CM_ "AUTOGENERATED FILE, DO NOT EDIT";

CM_ "lexus_ls600h.dbc starts here";
BU_: XXX CGW EPS SCM STM32G474_HRR CAN_Master

CM_ "Lexus LS600h candidate DBC derived from sustained CAN traffic in routes 9f2573520aa994fd/00000001--93ba1d9657 and 9f2573520aa994fd/00000004--52b0dd2646.";
CM_ "Only messages present in every segment of their source capture are included. One-shot diagnostic traffic is omitted; unknown messages use raw byte signals until their layouts are identified.";

BO_ 32 LS600H_020: 7 XXX
 SG_ LS600H_020_BYTE_0 : 0|8@1+ (1,0) [0|255] "" XXX
 SG_ LS600H_020_BYTE_1 : 8|8@1+ (1,0) [0|255] "" XXX
 SG_ LS600H_020_BYTE_2 : 16|8@1+ (1,0) [0|255] "" XXX
 SG_ LS600H_020_BYTE_3 : 24|8@1+ (1,0) [0|255] "" XXX
 SG_ LS600H_020_BYTE_4 : 32|8@1+ (1,0) [0|255] "" XXX
 SG_ LS600H_020_BYTE_5 : 40|8@1+ (1,0) [0|255] "" XXX
 SG_ LS600H_020_BYTE_6 : 48|8@1+ (1,0) [0|255] "" XXX
CM_ BO_ 32 "Observed continuously on bus 2 at approximately 80 Hz in the source route.";

BO_ 36 KINEMATICS: 8 XXX
 SG_ ACCEL_Y : 33|10@0+ (0.03589,-18.375) [0|65535] "m/s^2" XXX
 SG_ YAW_RATE : 1|10@0+ (0.244,-125) [0|65535] "deg/s" XXX
 SG_ ACCEL_X : 17|10@0+ (0.03589,-18.375) [0|65535] "m/s^2" XXX
CM_ BO_ 36 "Observed continuously on bus 2 at approximately 80 Hz in the source route.";

BO_ 37 STEER_ANGLE_SENSOR: 8 XXX
 SG_ STEER_ANGLE : 3|12@0- (1.5,0) [-500|500] "deg" XXX
 SG_ STEER_STATUS_2 : 16|8@1+ (1,0) [0|255] "" XXX
 SG_ STEER_STATUS_3 : 24|8@1+ (1,0) [0|255] "" XXX
 SG_ STEER_AUX_RAW_4 : 32|8@1+ (1,0) [0|255] "" XXX
 SG_ STEER_AUX_RAW_5 : 40|8@1+ (1,0) [0|255] "" XXX
 SG_ STEER_AUX_RAW_6 : 48|8@1+ (1,0) [0|255] "" XXX
 SG_ CHECKSUM : 63|8@0+ (1,0) [0|255] "" XXX
CM_ BO_ 37 "Observed continuously on bus 2 at approximately 80 Hz in the source route. Only STEER_ANGLE is validated for LS600h. In stationary steering route 0000002a--d4f3b01cd9, bytes 4 and 5 are identical in every frame, disproving the conventional Toyota STEER_FRACTION/STEER_RATE packing. Their meaning and byte 6 remain unknown.";
CM_ SG_ 37 STEER_AUX_RAW_4 "Steering-related raw byte; exactly equals STEER_AUX_RAW_5 in the stationary steering capture.";
CM_ SG_ 37 STEER_AUX_RAW_5 "Steering-related raw byte; exactly equals STEER_AUX_RAW_4 in the stationary steering capture.";
CM_ SG_ 37 CHECKSUM "Toyota checksum: (0x25 + 8 + sum(byte0..byte6)) & 0xff.";

BO_ 40 LS600H_STEER_028: 8 XXX
 SG_ STEER_INSHAFT_RAW : 3|12@0- (3.25,0) [-6656|6652.75] "deg" XXX
 SG_ STEER_RATE_EPS_RAW : 23|12@0- (1,0) [-2048|2047] "" XXX
 SG_ STEER_OUTSHAFT_RAW : 39|12@0- (3.25,0) [-6656|6652.75] "deg" XXX
 SG_ CHECKSUM : 63|8@0+ (1,0) [0|255] "" XXX
CM_ BO_ 40 "Observed continuously on bus 2 at approximately 80 Hz in the source route. Tentative EPS/steering-related frame; signal names are not 100% confirmed.";
CM_ SG_ 40 STEER_INSHAFT_RAW "Tentative input shaft resolver. In stationary steering route 9f2573520aa994fd/0000002a--d4f3b01cd9, corrected Motorola start bit 3 tracks 0x25 STEER_ANGLE with a full-route fit of 3.25314 deg/count and -10.80 deg offset. Uses the common 3.25 deg/count factor selected for the two shaft channels. Naming is based on the hypothesis that this channel is before the torsion bar; needs more confirmation.";
CM_ SG_ 40 STEER_RATE_EPS_RAW "Tentative EPS steering-rate channel. In stationary steering route 9f2573520aa994fd/0000002a--d4f3b01cd9, it has negligible correlation with absolute 0x25 STEER_ANGLE and strong correlation (r = 0.71 to 0.90) with its 100 ms smoothed derivative. The estimated scale varies from about 6 to 10 deg/s per count, so it remains unscaled pending a controlled rate calibration.";
CM_ SG_ 40 STEER_OUTSHAFT_RAW "Tentative output shaft resolver. In stationary steering route 9f2573520aa994fd/0000002a--d4f3b01cd9, it tracks 0x25 STEER_ANGLE with a full-route fit of 3.16874 deg/count and -11.03 deg offset. Uses the common 3.25 deg/count factor selected for the two shaft channels.";
CM_ SG_ 40 CHECKSUM "Observed checksum formula: (sum(byte0..byte6) + 0x30) & 0xff.";

BO_ 180 SPEED: 8 XXX
 SG_ ENCODER : 39|8@0+ (1,0) [0|255] "" XXX
 SG_ SPEED : 47|16@0+ (0.01,0) [0|250] "km/h" XXX
 SG_ CHECKSUM : 63|8@0+ (1,0) [0|255] "" XXX
CM_ BO_ 180 "Observed continuously on bus 2 at approximately 40 Hz in the source route.";

BO_ 182 LS600H_0B6: 4 XXX
 SG_ SPEED : 7|16@0+ (0.01,0) [0|250] "km/h" XXX
 SG_ STATUS : 23|8@0+ (1,0) [0|255] "" XXX
 SG_ CHECKSUM : 31|8@0+ (1,0) [0|255] "" XXX
CM_ BO_ 182 "Observed continuously on bus 2 at approximately 20 Hz in the source route. Tentative decode: compact vehicle speed/status/checksum frame; signal names are not 100% confirmed.";
CM_ SG_ 182 CHECKSUM "Observed checksum formula: (byte0 + byte1 + byte2 + 0xBA) & 0xff.";

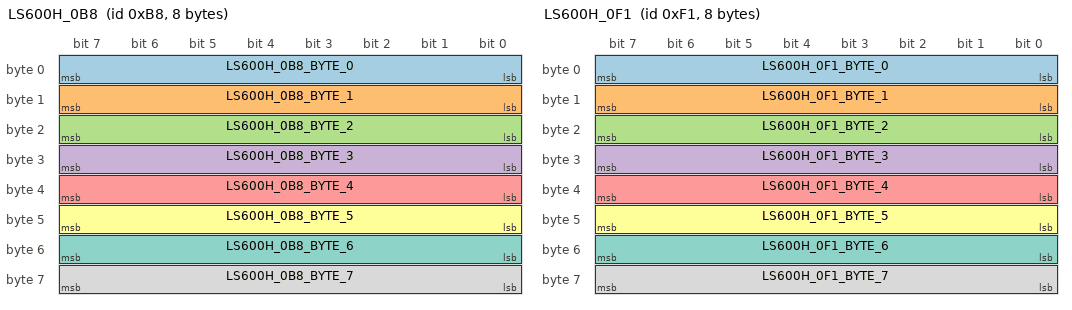
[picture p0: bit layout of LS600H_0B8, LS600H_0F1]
BO_ 184 LS600H_0B8: 8 XXX
 SG_ LS600H_0B8_BYTE_0 : 0|8@1+ (1,0) [0|255] "" XXX
 SG_ LS600H_0B8_BYTE_1 : 8|8@1+ (1,0) [0|255] "" XXX
 SG_ LS600H_0B8_BYTE_2 : 16|8@1+ (1,0) [0|255] "" XXX
 SG_ LS600H_0B8_BYTE_3 : 24|8@1+ (1,0) [0|255] "" XXX
 SG_ LS600H_0B8_BYTE_4 : 32|8@1+ (1,0) [0|255] "" XXX
 SG_ LS600H_0B8_BYTE_5 : 40|8@1+ (1,0) [0|255] "" XXX
 SG_ LS600H_0B8_BYTE_6 : 48|8@1+ (1,0) [0|255] "" XXX
 SG_ LS600H_0B8_BYTE_7 : 56|8@1+ (1,0) [0|255] "" XXX
CM_ BO_ 184 "Observed continuously on bus 2 at approximately 80 Hz in the source route.";

BO_ 241 LS600H_0F1: 8 XXX
 SG_ LS600H_0F1_BYTE_0 : 0|8@1+ (1,0) [0|255] "" XXX
 SG_ LS600H_0F1_BYTE_1 : 8|8@1+ (1,0) [0|255] "" XXX
 SG_ LS600H_0F1_BYTE_2 : 16|8@1+ (1,0) [0|255] "" XXX
 SG_ LS600H_0F1_BYTE_3 : 24|8@1+ (1,0) [0|255] "" XXX
 SG_ LS600H_0F1_BYTE_4 : 32|8@1+ (1,0) [0|255] "" XXX
 SG_ LS600H_0F1_BYTE_5 : 40|8@1+ (1,0) [0|255] "" XXX
 SG_ LS600H_0F1_BYTE_6 : 48|8@1+ (1,0) [0|255] "" XXX
 SG_ LS600H_0F1_BYTE_7 : 56|8@1+ (1,0) [0|255] "" XXX
CM_ BO_ 241 "Observed continuously on bus 2 at approximately 41.7 Hz in the source route.";

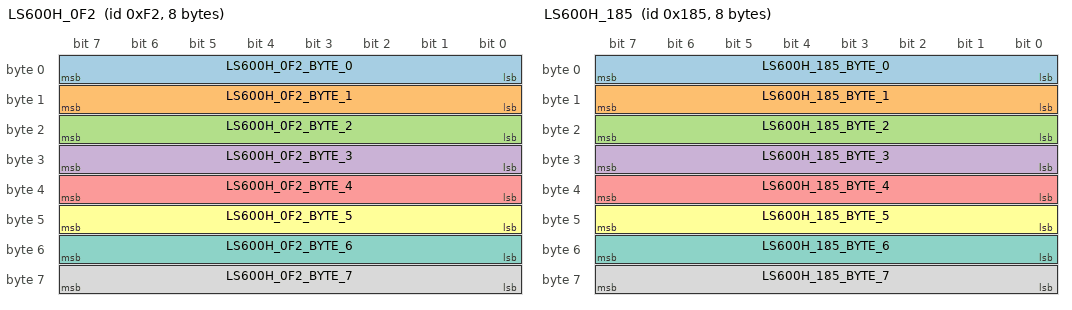
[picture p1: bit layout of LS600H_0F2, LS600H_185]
BO_ 242 LS600H_0F2: 8 XXX
 SG_ LS600H_0F2_BYTE_0 : 0|8@1+ (1,0) [0|255] "" XXX
 SG_ LS600H_0F2_BYTE_1 : 8|8@1+ (1,0) [0|255] "" XXX
 SG_ LS600H_0F2_BYTE_2 : 16|8@1+ (1,0) [0|255] "" XXX
 SG_ LS600H_0F2_BYTE_3 : 24|8@1+ (1,0) [0|255] "" XXX
 SG_ LS600H_0F2_BYTE_4 : 32|8@1+ (1,0) [0|255] "" XXX
 SG_ LS600H_0F2_BYTE_5 : 40|8@1+ (1,0) [0|255] "" XXX
 SG_ LS600H_0F2_BYTE_6 : 48|8@1+ (1,0) [0|255] "" XXX
 SG_ LS600H_0F2_BYTE_7 : 56|8@1+ (1,0) [0|255] "" XXX
CM_ BO_ 242 "Observed continuously on bus 2 at approximately 41.7 Hz in the source route.";

BO_ 384 STEERING_LKA: 5 XXX
 SG_ LKA_STATE : 31|8@0+ (1,0) [0|255] "" XXX
 SG_ STEER_REQUEST : 0|1@0+ (1,0) [0|1] "" XXX
 SG_ COUNTER : 6|6@0+ (1,0) [0|63] "" XXX
 SG_ SET_ME_1 : 7|1@0+ (1,0) [0|1] "" XXX
 SG_ STEER_TORQUE_CMD : 15|16@0- (1,0) [0|65535] "" XXX
 SG_ CHECKSUM : 39|8@0+ (1,0) [0|255] "" XXX
CM_ BO_ 384 "Matches standard Toyota STEERING_LKA command layout, but observed as static inactive 00 00 00 00 86 in LS600h logs so far.";

BO_ 385 LS600H_181: 6 XXX
 SG_ LS600H_181_BYTE_0 : 0|8@1+ (1,0) [0|255] "" XXX
 SG_ LS600H_181_BYTE_1 : 8|8@1+ (1,0) [0|255] "" XXX
 SG_ LS600H_181_BYTE_2 : 16|8@1+ (1,0) [0|255] "" XXX
 SG_ LS600H_181_BYTE_3 : 24|8@1+ (1,0) [0|255] "" XXX
 SG_ LS600H_181_BYTE_4 : 32|8@1+ (1,0) [0|255] "" XXX
 SG_ LS600H_181_BYTE_5 : 40|8@1+ (1,0) [0|255] "" XXX
CM_ BO_ 385 "Observed continuously on bus 2 at approximately 62.5 Hz in the source route.";

BO_ 386 LS600H_182: 7 XXX
 SG_ LS600H_182_BYTE_0 : 0|8@1+ (1,0) [0|255] "" XXX
 SG_ LS600H_182_BYTE_1 : 8|8@1+ (1,0) [0|255] "" XXX
 SG_ LS600H_182_BYTE_2 : 16|8@1+ (1,0) [0|255] "" XXX
 SG_ LS600H_182_BYTE_3 : 24|8@1+ (1,0) [0|255] "" XXX
 SG_ LS600H_182_BYTE_4 : 32|8@1+ (1,0) [0|255] "" XXX
 SG_ LS600H_182_BYTE_5 : 40|8@1+ (1,0) [0|255] "" XXX
 SG_ LS600H_182_BYTE_6 : 48|8@1+ (1,0) [0|255] "" XXX
CM_ BO_ 386 "Observed continuously on bus 2 at approximately 62.5 Hz in the source route.";

BO_ 389 LS600H_185: 8 XXX
 SG_ LS600H_185_BYTE_0 : 0|8@1+ (1,0) [0|255] "" XXX
 SG_ LS600H_185_BYTE_1 : 8|8@1+ (1,0) [0|255] "" XXX
 SG_ LS600H_185_BYTE_2 : 16|8@1+ (1,0) [0|255] "" XXX
 SG_ LS600H_185_BYTE_3 : 24|8@1+ (1,0) [0|255] "" XXX
 SG_ LS600H_185_BYTE_4 : 32|8@1+ (1,0) [0|255] "" XXX
 SG_ LS600H_185_BYTE_5 : 40|8@1+ (1,0) [0|255] "" XXX
 SG_ LS600H_185_BYTE_6 : 48|8@1+ (1,0) [0|255] "" XXX
 SG_ LS600H_185_BYTE_7 : 56|8@1+ (1,0) [0|255] "" XXX
CM_ BO_ 389 "Observed continuously on bus 2 at approximately 62.5 Hz in the source route.";

BO_ 548 BRAKE_MODULE: 8 XXX
 SG_ BRAKE_PRESSURE : 43|12@0+ (1,0) [0|4047] "" XXX
 SG_ BRAKE_PRESSED : 5|1@0+ (1,0) [0|1] "" XXX
 SG_ TENTATIVE_BRAKE_ACTIVITY : 46|1@1+ (1,0) [0|1] "" XXX
CM_ BO_ 548 "Observed on LS600h as a brake/status frame. Multi-route ACC/decel scan showed this is not an ACC command frame; most samples are zero, with pressure/status-like bytes changing during brake activity.";
CM_ SG_ 548 TENTATIVE_BRAKE_ACTIVITY "Unconfirmed raw byte5 mask 0x40. Correlates with VSC1S07 BRKON in the available routes but is not confirmed as a discrete brake state.";
CM_ BU_ XXX "LS600h DBC note: some addresses are bus-dependent. Address 0x224 is brake/status on bus 0/1 in current logs, while bus 2 also carries radar-track-like data at the same address. DBC files cannot disambiguate by bus, so the bus 2 0x224 radar slot is intentionally not added as a duplicate BO_ definition.";

BO_ 550 LS600H_BRAKE_MODULE_226: 8 XXX
 SG_ BRAKE_PRESSURE : 0|9@0+ (1,0) [0|511] "" XXX
 SG_ BRAKE_POSITION : 16|9@0+ (1,0) [0|511] "" XXX
 SG_ BRAKE_PRESSED : 37|1@0+ (1,0) [0|1] "" XXX
CM_ BO_ 550 "Matched by address and DLC to toyota_tnga_k_pt.dbc/toyota_nodsu_pt.dbc BRAKE_MODULE; observed continuously on bus 2 at approximately 20 Hz in route ff528bde139e99de/0000051e--6ae54d23d9.";
CM_ BU_ XXX "LS600h DBC note: address 0x226 is brake/status on bus 1 in earlier logs and radar-track-like on bus 2 in later logs. This DBC keeps the existing brake/status definition and does not add a duplicate bus 2 radar-track BO_ for 0x226.";
CM_ SG_ 550 BRAKE_PRESSURE "Known Toyota layout: seems proportional to pedal force.";
CM_ SG_ 550 BRAKE_POSITION "Known Toyota layout: seems proportional to pedal displacement.";

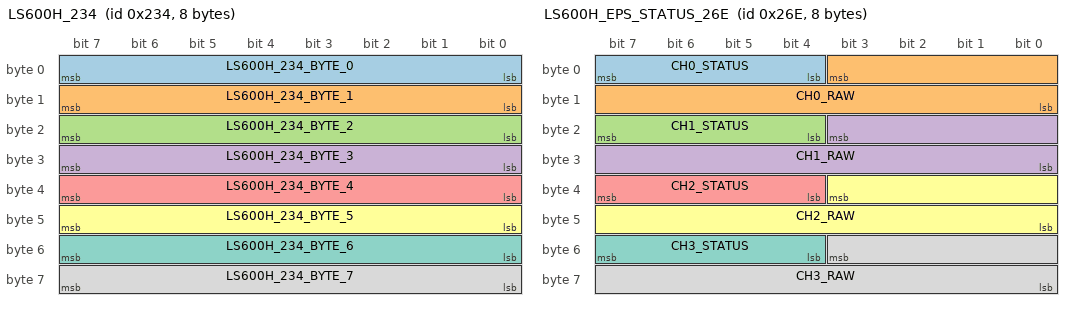
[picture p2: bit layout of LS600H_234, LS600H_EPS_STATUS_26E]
BO_ 564 LS600H_234: 8 XXX
 SG_ LS600H_234_BYTE_0 : 0|8@1+ (1,0) [0|255] "" XXX
 SG_ LS600H_234_BYTE_1 : 8|8@1+ (1,0) [0|255] "" XXX
 SG_ LS600H_234_BYTE_2 : 16|8@1+ (1,0) [0|255] "" XXX
 SG_ LS600H_234_BYTE_3 : 24|8@1+ (1,0) [0|255] "" XXX
 SG_ LS600H_234_BYTE_4 : 32|8@1+ (1,0) [0|255] "" XXX
 SG_ LS600H_234_BYTE_5 : 40|8@1+ (1,0) [0|255] "" XXX
 SG_ LS600H_234_BYTE_6 : 48|8@1+ (1,0) [0|255] "" XXX
 SG_ LS600H_234_BYTE_7 : 56|8@1+ (1,0) [0|255] "" XXX
CM_ BO_ 564 "Observed continuously on bus 2 at approximately 40 Hz in the source route.";

BO_ 608 STEER_TORQUE_SENSOR: 8 XXX
 SG_ STEER_TORQUE_EPS : 47|16@0- (1,0) [-32768|32767] "" XXX
 SG_ STEER_TORQUE_DRIVER : 15|16@0- (1,0) [-32768|32767] "" XXX
 SG_ STEER_ANGLE : 31|16@0- (0.0573,0) [-500|500] "" XXX
 SG_ STEER_ANGLE_INITIALIZING : 3|1@0+ (1,0) [0|1] "" XXX
 SG_ STEER_OVERRIDE : 0|1@0+ (1,0) [0|1] "" XXX
 SG_ CHECKSUM : 63|8@0+ (1,0) [0|255] "" XXX
CM_ BO_ 608 "Observed continuously on bus 2 at approximately 49.5 Hz in the source route.";

BO_ 622 LS600H_EPS_STATUS_26E: 8 XXX
 SG_ CH0_STATUS : 7|4@0+ (1,0) [0|15] "" XXX
 SG_ CH0_RAW : 3|12@0+ (1,0) [0|4095] "" XXX
 SG_ CH1_STATUS : 23|4@0+ (1,0) [0|15] "" XXX
 SG_ CH1_RAW : 19|12@0+ (1,0) [0|4095] "" XXX
 SG_ CH2_STATUS : 39|4@0+ (1,0) [0|15] "" XXX
 SG_ CH2_RAW : 35|12@0+ (1,0) [0|4095] "" XXX
 SG_ CH3_STATUS : 55|4@0+ (1,0) [0|15] "" XXX
 SG_ CH3_RAW : 51|12@0+ (1,0) [0|4095] "" XXX
CM_ BO_ 622 "Observed continuously on bus 2 at approximately 27.8 Hz in the source route. Tentative coarse EPS/status raw-channel frame; signal names are not 100% confirmed.";

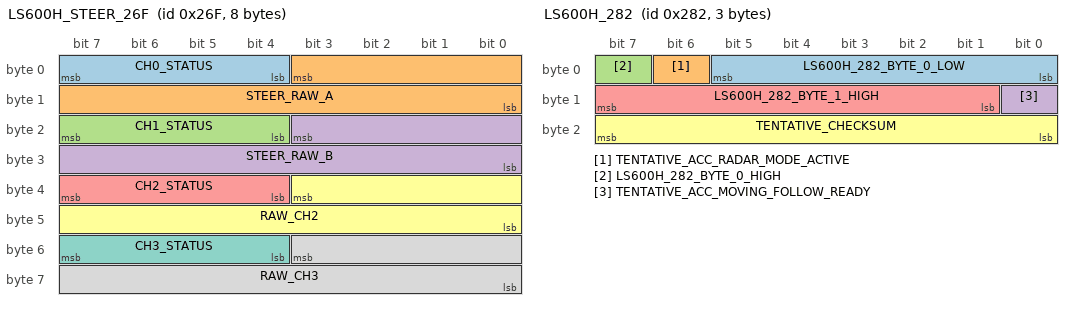
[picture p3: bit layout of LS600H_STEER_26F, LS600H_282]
BO_ 623 LS600H_STEER_26F: 8 XXX
 SG_ CH0_STATUS : 7|4@0+ (1,0) [0|15] "" XXX
 SG_ STEER_RAW_A : 3|12@0+ (1,0) [0|4095] "" XXX
 SG_ CH1_STATUS : 23|4@0+ (1,0) [0|15] "" XXX
 SG_ STEER_RAW_B : 19|12@0+ (1,0) [0|4095] "" XXX
 SG_ CH2_STATUS : 39|4@0+ (1,0) [0|15] "" XXX
 SG_ RAW_CH2 : 35|12@0+ (1,0) [0|4095] "" XXX
 SG_ CH3_STATUS : 55|4@0+ (1,0) [0|15] "" XXX
 SG_ RAW_CH3 : 51|12@0+ (1,0) [0|4095] "" XXX
CM_ BO_ 623 "Observed continuously on bus 2 at approximately 41.7 Hz in the source route. Tentative steering/EPS raw multi-channel frame; signal names are not 100% confirmed.";
CM_ SG_ 623 STEER_RAW_A "Strongly anti-correlates with steering angle in the stationary steering sweep. Local fit only: steering angle deg ~= -5.90 * raw + 3762.7.";
CM_ SG_ 623 STEER_RAW_B "Strongly correlates with steering angle in the stationary steering sweep. Local fit only: steering angle deg ~= 5.36 * raw - 3346.8.";

BO_ 641 LS600H_LEAD_INFO: 6 XXX
 SG_ LEAD_REL_SPEED : 0|8@1- (0.1,0) [-12.8|12.7] "m/s" XXX
 SG_ LEAD_LONG_DIST : 8|8@1+ (1,0) [0|255] "m" XXX
 SG_ LS600H_281_BYTE_2 : 16|8@1+ (1,0) [0|255] "" XXX
 SG_ LS600H_281_BYTE_3 : 24|8@1+ (1,0) [0|255] "" XXX
 SG_ LS600H_281_BYTE_4 : 32|8@1+ (1,0) [0|255] "" XXX
 SG_ TENTATIVE_CHECKSUM : 40|8@1+ (1,0) [0|255] "" XXX
CM_ BO_ 641 "Observed continuously on bus 0 at approximately 31.3 Hz across LS600h routes. Tentative radar lead-info layout; useful for lead presence/distance but not an ACC command frame.";
CM_ SG_ 641 LEAD_REL_SPEED "Tentative signed relative speed. Byte value correlated weakly with model/radarState lead relative speed; scale needs confirmation.";
CM_ SG_ 641 LEAD_LONG_DIST "Tentative lead distance in meters. 0xff was observed when no lead was visible. During visual lead windows this tracks model/radarState lead distance with roughly +2 m average offset.";
CM_ SG_ 641 TENTATIVE_CHECKSUM "Tentative checksum appears to be (LEAD_REL_SPEED raw byte + LEAD_LONG_DIST raw byte + 0x89) & 0xff in the observed route.";
VAL_ 641 LEAD_LONG_DIST 255 "NO_LEAD" ;

BO_ 642 LS600H_282: 3 XXX
 SG_ LS600H_282_BYTE_0_LOW : 0|6@1+ (1,0) [0|63] "" XXX
 SG_ TENTATIVE_ACC_RADAR_MODE_ACTIVE : 6|1@1+ (1,0) [0|1] "" XXX
 SG_ LS600H_282_BYTE_0_HIGH : 7|1@1+ (1,0) [0|1] "" XXX
 SG_ TENTATIVE_ACC_MOVING_FOLLOW_READY : 8|1@1+ (1,0) [0|1] "" XXX
 SG_ LS600H_282_BYTE_1_HIGH : 9|7@1+ (1,0) [0|127] "" XXX
 SG_ TENTATIVE_CHECKSUM : 16|8@1+ (1,0) [0|255] "" XXX
CM_ BO_ 642 "Observed continuously on bus 0 at approximately 31.3 Hz across LS600h routes. Radar/ACC status candidate, not an ACC command frame. In the 2026-06-30 ACC comparison, regular non-ACC cruise stayed at 000087, ACC moving/follow states used 4001c8, and ACC standstill hold used 4000c7.";
CM_ SG_ 642 TENTATIVE_ACC_RADAR_MODE_ACTIVE "Unconfirmed raw byte0 mask 0x40. Clear separator between regular cruise and ACC/radar-follow mode in routes 00000004--2809598fb3, 00000005--225e17a206, and 00000006--0500d7b8dc.";
CM_ SG_ 642 TENTATIVE_ACC_MOVING_FOLLOW_READY "Unconfirmed raw byte1 mask 0x01. High in ACC moving/follow-ready state 4001c8, low in ACC standstill/hold state 4000c7, and low when inactive 000087.";
CM_ SG_ 642 TENTATIVE_CHECKSUM "Tentative checksum-like byte. Observed states fit byte2 = (byte0 + byte1 + 0x87) & 0xff for common values 000087, 4000c7, and 4001c8.";
VAL_ 642 TENTATIVE_ACC_RADAR_MODE_ACTIVE 0 "INACTIVE_OR_REGULAR_CRUISE" 1 "ACC_RADAR_MODE_ACTIVE" ;
VAL_ 642 TENTATIVE_ACC_MOVING_FOLLOW_READY 0 "INACTIVE_OR_STANDSTILL_HOLD" 1 "ACC_MOVING_FOLLOW_READY" ;

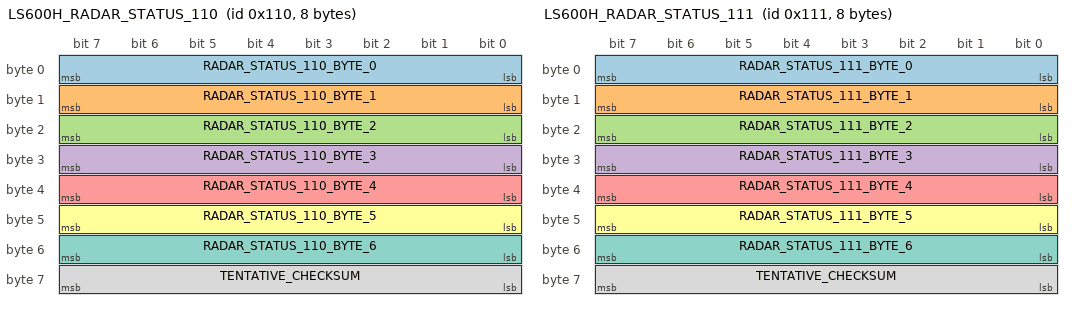
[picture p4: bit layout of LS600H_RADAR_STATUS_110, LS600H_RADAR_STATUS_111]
BO_ 272 LS600H_RADAR_STATUS_110: 8 XXX
 SG_ RADAR_STATUS_110_BYTE_0 : 0|8@1+ (1,0) [0|255] "" XXX
 SG_ RADAR_STATUS_110_BYTE_1 : 8|8@1+ (1,0) [0|255] "" XXX
 SG_ RADAR_STATUS_110_BYTE_2 : 16|8@1+ (1,0) [0|255] "" XXX
 SG_ RADAR_STATUS_110_BYTE_3 : 24|8@1+ (1,0) [0|255] "" XXX
 SG_ RADAR_STATUS_110_BYTE_4 : 32|8@1+ (1,0) [0|255] "" XXX
 SG_ RADAR_STATUS_110_BYTE_5 : 40|8@1+ (1,0) [0|255] "" XXX
 SG_ RADAR_STATUS_110_BYTE_6 : 48|8@1+ (1,0) [0|255] "" XXX
 SG_ TENTATIVE_CHECKSUM : 56|8@1+ (1,0) [0|255] "" XXX
CM_ BO_ 272 "Tentative bus 2 front radar/object-recognition ECU status/config frame. Observed in ACC and regular-cruise comparison routes; byte layout is not decoded.";

BO_ 273 LS600H_RADAR_STATUS_111: 8 XXX
 SG_ RADAR_STATUS_111_BYTE_0 : 0|8@1+ (1,0) [0|255] "" XXX
 SG_ RADAR_STATUS_111_BYTE_1 : 8|8@1+ (1,0) [0|255] "" XXX
 SG_ RADAR_STATUS_111_BYTE_2 : 16|8@1+ (1,0) [0|255] "" XXX
 SG_ RADAR_STATUS_111_BYTE_3 : 24|8@1+ (1,0) [0|255] "" XXX
 SG_ RADAR_STATUS_111_BYTE_4 : 32|8@1+ (1,0) [0|255] "" XXX
 SG_ RADAR_STATUS_111_BYTE_5 : 40|8@1+ (1,0) [0|255] "" XXX
 SG_ RADAR_STATUS_111_BYTE_6 : 48|8@1+ (1,0) [0|255] "" XXX
 SG_ TENTATIVE_CHECKSUM : 56|8@1+ (1,0) [0|255] "" XXX
CM_ BO_ 273 "Tentative bus 2 front radar/object-recognition ECU status/config frame. Observed in ACC and regular-cruise comparison routes; byte layout is not decoded.";

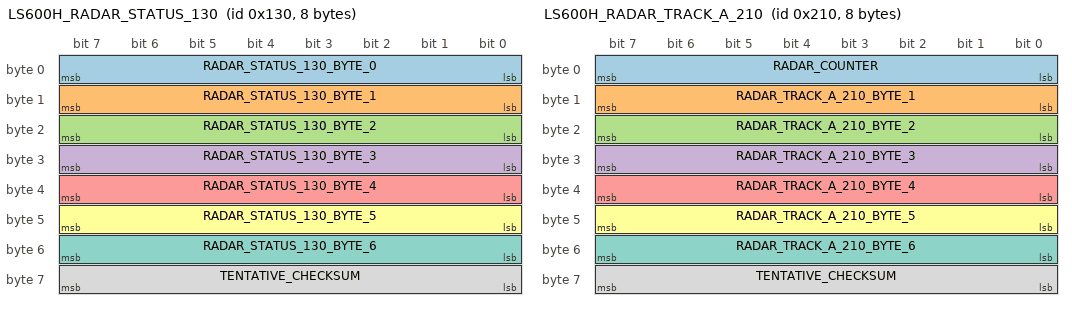
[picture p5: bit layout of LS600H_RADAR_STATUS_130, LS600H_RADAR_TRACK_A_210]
BO_ 304 LS600H_RADAR_STATUS_130: 8 XXX
 SG_ RADAR_STATUS_130_BYTE_0 : 0|8@1+ (1,0) [0|255] "" XXX
 SG_ RADAR_STATUS_130_BYTE_1 : 8|8@1+ (1,0) [0|255] "" XXX
 SG_ RADAR_STATUS_130_BYTE_2 : 16|8@1+ (1,0) [0|255] "" XXX
 SG_ RADAR_STATUS_130_BYTE_3 : 24|8@1+ (1,0) [0|255] "" XXX
 SG_ RADAR_STATUS_130_BYTE_4 : 32|8@1+ (1,0) [0|255] "" XXX
 SG_ RADAR_STATUS_130_BYTE_5 : 40|8@1+ (1,0) [0|255] "" XXX
 SG_ RADAR_STATUS_130_BYTE_6 : 48|8@1+ (1,0) [0|255] "" XXX
 SG_ TENTATIVE_CHECKSUM : 56|8@1+ (1,0) [0|255] "" XXX
CM_ BO_ 304 "Tentative bus 2 front radar/object-recognition ECU status/config frame. Payload changes during radar/object activity but exact fields are not decoded.";

BO_ 528 LS600H_RADAR_TRACK_A_210: 8 XXX
 SG_ RADAR_COUNTER : 0|8@1+ (1,0) [0|255] "" XXX
 SG_ RADAR_TRACK_A_210_BYTE_1 : 8|8@1+ (1,0) [0|255] "" XXX
 SG_ RADAR_TRACK_A_210_BYTE_2 : 16|8@1+ (1,0) [0|255] "" XXX
 SG_ RADAR_TRACK_A_210_BYTE_3 : 24|8@1+ (1,0) [0|255] "" XXX
 SG_ RADAR_TRACK_A_210_BYTE_4 : 32|8@1+ (1,0) [0|255] "" XXX
 SG_ RADAR_TRACK_A_210_BYTE_5 : 40|8@1+ (1,0) [0|255] "" XXX
 SG_ RADAR_TRACK_A_210_BYTE_6 : 48|8@1+ (1,0) [0|255] "" XXX
 SG_ TENTATIVE_CHECKSUM : 56|8@1+ (1,0) [0|255] "" XXX
CM_ BO_ 528 "Tentative bus 2 radar object track frame. Address matches Toyota older ADAS TRACK_A_0 family, but LS600h bit layout/scales are not confirmed; byte0 is a rolling counter and byte7 is checksum-like.";

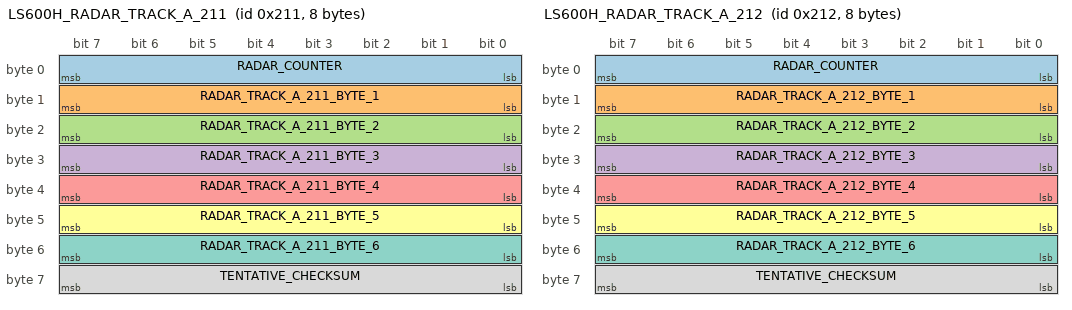
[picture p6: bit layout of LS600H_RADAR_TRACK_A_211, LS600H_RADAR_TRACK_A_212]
BO_ 529 LS600H_RADAR_TRACK_A_211: 8 XXX
 SG_ RADAR_COUNTER : 0|8@1+ (1,0) [0|255] "" XXX
 SG_ RADAR_TRACK_A_211_BYTE_1 : 8|8@1+ (1,0) [0|255] "" XXX
 SG_ RADAR_TRACK_A_211_BYTE_2 : 16|8@1+ (1,0) [0|255] "" XXX
 SG_ RADAR_TRACK_A_211_BYTE_3 : 24|8@1+ (1,0) [0|255] "" XXX
 SG_ RADAR_TRACK_A_211_BYTE_4 : 32|8@1+ (1,0) [0|255] "" XXX
 SG_ RADAR_TRACK_A_211_BYTE_5 : 40|8@1+ (1,0) [0|255] "" XXX
 SG_ RADAR_TRACK_A_211_BYTE_6 : 48|8@1+ (1,0) [0|255] "" XXX
 SG_ TENTATIVE_CHECKSUM : 56|8@1+ (1,0) [0|255] "" XXX
CM_ BO_ 529 "Tentative bus 2 radar object track frame. Address matches Toyota older ADAS TRACK_A_1 family; LS600h bit layout/scales are not confirmed.";

BO_ 530 LS600H_RADAR_TRACK_A_212: 8 XXX
 SG_ RADAR_COUNTER : 0|8@1+ (1,0) [0|255] "" XXX
 SG_ RADAR_TRACK_A_212_BYTE_1 : 8|8@1+ (1,0) [0|255] "" XXX
 SG_ RADAR_TRACK_A_212_BYTE_2 : 16|8@1+ (1,0) [0|255] "" XXX
 SG_ RADAR_TRACK_A_212_BYTE_3 : 24|8@1+ (1,0) [0|255] "" XXX
 SG_ RADAR_TRACK_A_212_BYTE_4 : 32|8@1+ (1,0) [0|255] "" XXX
 SG_ RADAR_TRACK_A_212_BYTE_5 : 40|8@1+ (1,0) [0|255] "" XXX
 SG_ RADAR_TRACK_A_212_BYTE_6 : 48|8@1+ (1,0) [0|255] "" XXX
 SG_ TENTATIVE_CHECKSUM : 56|8@1+ (1,0) [0|255] "" XXX
CM_ BO_ 530 "Tentative bus 2 radar object track frame. Address matches Toyota older ADAS TRACK_A_2 family; LS600h bit layout/scales are not confirmed.";

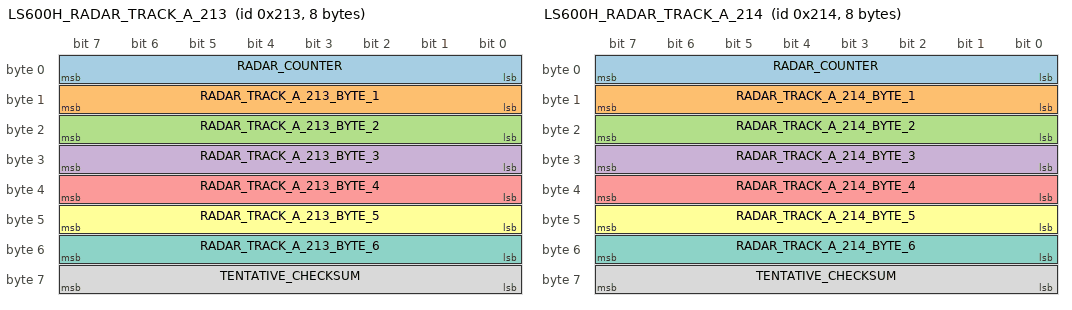
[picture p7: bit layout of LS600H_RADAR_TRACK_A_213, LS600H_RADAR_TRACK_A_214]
BO_ 531 LS600H_RADAR_TRACK_A_213: 8 XXX
 SG_ RADAR_COUNTER : 0|8@1+ (1,0) [0|255] "" XXX
 SG_ RADAR_TRACK_A_213_BYTE_1 : 8|8@1+ (1,0) [0|255] "" XXX
 SG_ RADAR_TRACK_A_213_BYTE_2 : 16|8@1+ (1,0) [0|255] "" XXX
 SG_ RADAR_TRACK_A_213_BYTE_3 : 24|8@1+ (1,0) [0|255] "" XXX
 SG_ RADAR_TRACK_A_213_BYTE_4 : 32|8@1+ (1,0) [0|255] "" XXX
 SG_ RADAR_TRACK_A_213_BYTE_5 : 40|8@1+ (1,0) [0|255] "" XXX
 SG_ RADAR_TRACK_A_213_BYTE_6 : 48|8@1+ (1,0) [0|255] "" XXX
 SG_ TENTATIVE_CHECKSUM : 56|8@1+ (1,0) [0|255] "" XXX
CM_ BO_ 531 "Tentative bus 2 radar object track frame. Address matches Toyota older ADAS TRACK_A_3 family; LS600h bit layout/scales are not confirmed.";

BO_ 532 LS600H_RADAR_TRACK_A_214: 8 XXX
 SG_ RADAR_COUNTER : 0|8@1+ (1,0) [0|255] "" XXX
 SG_ RADAR_TRACK_A_214_BYTE_1 : 8|8@1+ (1,0) [0|255] "" XXX
 SG_ RADAR_TRACK_A_214_BYTE_2 : 16|8@1+ (1,0) [0|255] "" XXX
 SG_ RADAR_TRACK_A_214_BYTE_3 : 24|8@1+ (1,0) [0|255] "" XXX
 SG_ RADAR_TRACK_A_214_BYTE_4 : 32|8@1+ (1,0) [0|255] "" XXX
 SG_ RADAR_TRACK_A_214_BYTE_5 : 40|8@1+ (1,0) [0|255] "" XXX
 SG_ RADAR_TRACK_A_214_BYTE_6 : 48|8@1+ (1,0) [0|255] "" XXX
 SG_ TENTATIVE_CHECKSUM : 56|8@1+ (1,0) [0|255] "" XXX
CM_ BO_ 532 "Tentative bus 2 radar object track frame. Address matches Toyota older ADAS TRACK_A_4 family; LS600h bit layout/scales are not confirmed.";

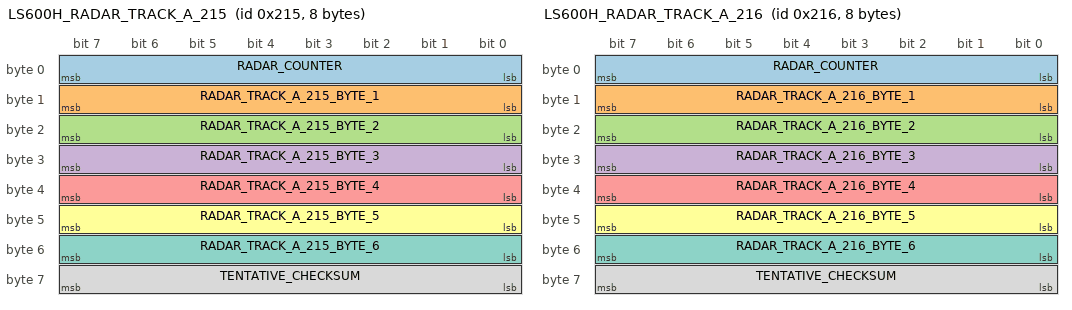
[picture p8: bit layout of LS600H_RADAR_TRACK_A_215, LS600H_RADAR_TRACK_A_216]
BO_ 533 LS600H_RADAR_TRACK_A_215: 8 XXX
 SG_ RADAR_COUNTER : 0|8@1+ (1,0) [0|255] "" XXX
 SG_ RADAR_TRACK_A_215_BYTE_1 : 8|8@1+ (1,0) [0|255] "" XXX
 SG_ RADAR_TRACK_A_215_BYTE_2 : 16|8@1+ (1,0) [0|255] "" XXX
 SG_ RADAR_TRACK_A_215_BYTE_3 : 24|8@1+ (1,0) [0|255] "" XXX
 SG_ RADAR_TRACK_A_215_BYTE_4 : 32|8@1+ (1,0) [0|255] "" XXX
 SG_ RADAR_TRACK_A_215_BYTE_5 : 40|8@1+ (1,0) [0|255] "" XXX
 SG_ RADAR_TRACK_A_215_BYTE_6 : 48|8@1+ (1,0) [0|255] "" XXX
 SG_ TENTATIVE_CHECKSUM : 56|8@1+ (1,0) [0|255] "" XXX
CM_ BO_ 533 "Tentative bus 2 radar object track frame. Address matches Toyota older ADAS TRACK_A_5 family; LS600h bit layout/scales are not confirmed.";

BO_ 534 LS600H_RADAR_TRACK_A_216: 8 XXX
 SG_ RADAR_COUNTER : 0|8@1+ (1,0) [0|255] "" XXX
 SG_ RADAR_TRACK_A_216_BYTE_1 : 8|8@1+ (1,0) [0|255] "" XXX
 SG_ RADAR_TRACK_A_216_BYTE_2 : 16|8@1+ (1,0) [0|255] "" XXX
 SG_ RADAR_TRACK_A_216_BYTE_3 : 24|8@1+ (1,0) [0|255] "" XXX
 SG_ RADAR_TRACK_A_216_BYTE_4 : 32|8@1+ (1,0) [0|255] "" XXX
 SG_ RADAR_TRACK_A_216_BYTE_5 : 40|8@1+ (1,0) [0|255] "" XXX
 SG_ RADAR_TRACK_A_216_BYTE_6 : 48|8@1+ (1,0) [0|255] "" XXX
 SG_ TENTATIVE_CHECKSUM : 56|8@1+ (1,0) [0|255] "" XXX
CM_ BO_ 534 "Tentative bus 2 radar object track frame. Address matches Toyota older ADAS TRACK_A_6 family; LS600h bit layout/scales are not confirmed.";

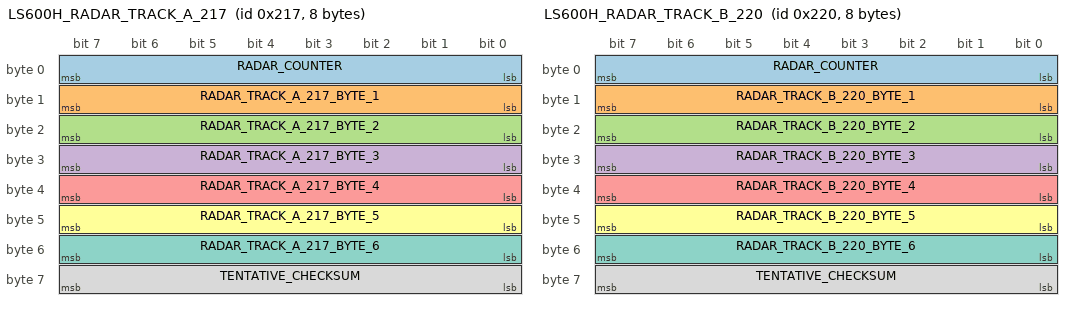
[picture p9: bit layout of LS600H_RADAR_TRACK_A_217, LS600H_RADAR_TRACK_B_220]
BO_ 535 LS600H_RADAR_TRACK_A_217: 8 XXX
 SG_ RADAR_COUNTER : 0|8@1+ (1,0) [0|255] "" XXX
 SG_ RADAR_TRACK_A_217_BYTE_1 : 8|8@1+ (1,0) [0|255] "" XXX
 SG_ RADAR_TRACK_A_217_BYTE_2 : 16|8@1+ (1,0) [0|255] "" XXX
 SG_ RADAR_TRACK_A_217_BYTE_3 : 24|8@1+ (1,0) [0|255] "" XXX
 SG_ RADAR_TRACK_A_217_BYTE_4 : 32|8@1+ (1,0) [0|255] "" XXX
 SG_ RADAR_TRACK_A_217_BYTE_5 : 40|8@1+ (1,0) [0|255] "" XXX
 SG_ RADAR_TRACK_A_217_BYTE_6 : 48|8@1+ (1,0) [0|255] "" XXX
 SG_ TENTATIVE_CHECKSUM : 56|8@1+ (1,0) [0|255] "" XXX
CM_ BO_ 535 "Tentative bus 2 radar object track frame. Address matches Toyota older ADAS TRACK_A_7 family; LS600h bit layout/scales are not confirmed.";

BO_ 544 LS600H_RADAR_TRACK_B_220: 8 XXX
 SG_ RADAR_COUNTER : 0|8@1+ (1,0) [0|255] "" XXX
 SG_ RADAR_TRACK_B_220_BYTE_1 : 8|8@1+ (1,0) [0|255] "" XXX
 SG_ RADAR_TRACK_B_220_BYTE_2 : 16|8@1+ (1,0) [0|255] "" XXX
 SG_ RADAR_TRACK_B_220_BYTE_3 : 24|8@1+ (1,0) [0|255] "" XXX
 SG_ RADAR_TRACK_B_220_BYTE_4 : 32|8@1+ (1,0) [0|255] "" XXX
 SG_ RADAR_TRACK_B_220_BYTE_5 : 40|8@1+ (1,0) [0|255] "" XXX
 SG_ RADAR_TRACK_B_220_BYTE_6 : 48|8@1+ (1,0) [0|255] "" XXX
 SG_ TENTATIVE_CHECKSUM : 56|8@1+ (1,0) [0|255] "" XXX
CM_ BO_ 544 "Tentative bus 2 radar object track/status frame. Address matches Toyota older ADAS TRACK_B_0 family, but LS600h layout/scales are not confirmed; byte0 is a rolling counter and byte7 is checksum-like.";

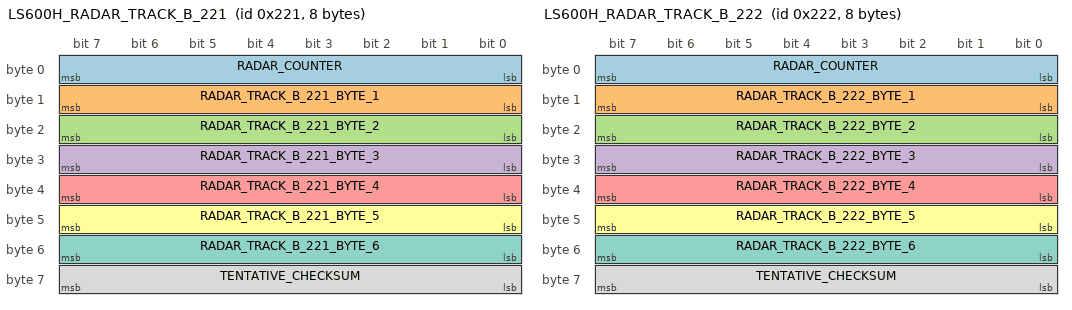
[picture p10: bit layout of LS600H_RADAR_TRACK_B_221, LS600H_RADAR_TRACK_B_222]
BO_ 545 LS600H_RADAR_TRACK_B_221: 8 XXX
 SG_ RADAR_COUNTER : 0|8@1+ (1,0) [0|255] "" XXX
 SG_ RADAR_TRACK_B_221_BYTE_1 : 8|8@1+ (1,0) [0|255] "" XXX
 SG_ RADAR_TRACK_B_221_BYTE_2 : 16|8@1+ (1,0) [0|255] "" XXX
 SG_ RADAR_TRACK_B_221_BYTE_3 : 24|8@1+ (1,0) [0|255] "" XXX
 SG_ RADAR_TRACK_B_221_BYTE_4 : 32|8@1+ (1,0) [0|255] "" XXX
 SG_ RADAR_TRACK_B_221_BYTE_5 : 40|8@1+ (1,0) [0|255] "" XXX
 SG_ RADAR_TRACK_B_221_BYTE_6 : 48|8@1+ (1,0) [0|255] "" XXX
 SG_ TENTATIVE_CHECKSUM : 56|8@1+ (1,0) [0|255] "" XXX
CM_ BO_ 545 "Tentative bus 2 radar object track/status frame. Address matches Toyota older ADAS TRACK_B_1 family; LS600h layout/scales are not confirmed.";

BO_ 546 LS600H_RADAR_TRACK_B_222: 8 XXX
 SG_ RADAR_COUNTER : 0|8@1+ (1,0) [0|255] "" XXX
 SG_ RADAR_TRACK_B_222_BYTE_1 : 8|8@1+ (1,0) [0|255] "" XXX
 SG_ RADAR_TRACK_B_222_BYTE_2 : 16|8@1+ (1,0) [0|255] "" XXX
 SG_ RADAR_TRACK_B_222_BYTE_3 : 24|8@1+ (1,0) [0|255] "" XXX
 SG_ RADAR_TRACK_B_222_BYTE_4 : 32|8@1+ (1,0) [0|255] "" XXX
 SG_ RADAR_TRACK_B_222_BYTE_5 : 40|8@1+ (1,0) [0|255] "" XXX
 SG_ RADAR_TRACK_B_222_BYTE_6 : 48|8@1+ (1,0) [0|255] "" XXX
 SG_ TENTATIVE_CHECKSUM : 56|8@1+ (1,0) [0|255] "" XXX
CM_ BO_ 546 "Tentative bus 2 radar object track/status frame. Address matches Toyota older ADAS TRACK_B_2 family; LS600h layout/scales are not confirmed.";

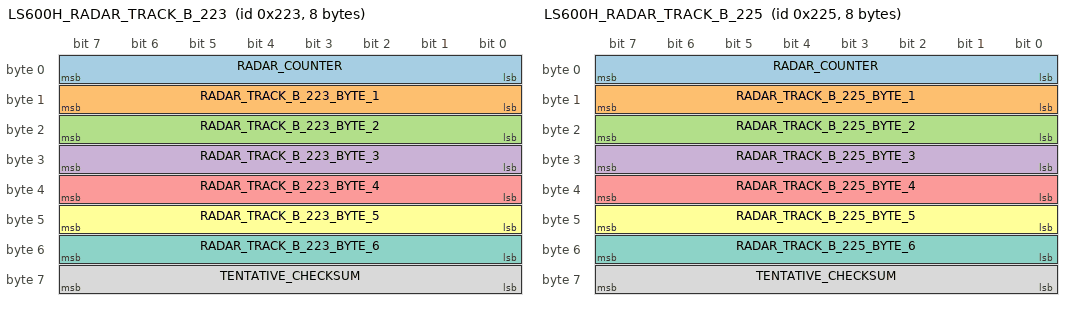
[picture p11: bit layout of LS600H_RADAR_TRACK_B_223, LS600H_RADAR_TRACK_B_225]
BO_ 547 LS600H_RADAR_TRACK_B_223: 8 XXX
 SG_ RADAR_COUNTER : 0|8@1+ (1,0) [0|255] "" XXX
 SG_ RADAR_TRACK_B_223_BYTE_1 : 8|8@1+ (1,0) [0|255] "" XXX
 SG_ RADAR_TRACK_B_223_BYTE_2 : 16|8@1+ (1,0) [0|255] "" XXX
 SG_ RADAR_TRACK_B_223_BYTE_3 : 24|8@1+ (1,0) [0|255] "" XXX
 SG_ RADAR_TRACK_B_223_BYTE_4 : 32|8@1+ (1,0) [0|255] "" XXX
 SG_ RADAR_TRACK_B_223_BYTE_5 : 40|8@1+ (1,0) [0|255] "" XXX
 SG_ RADAR_TRACK_B_223_BYTE_6 : 48|8@1+ (1,0) [0|255] "" XXX
 SG_ TENTATIVE_CHECKSUM : 56|8@1+ (1,0) [0|255] "" XXX
CM_ BO_ 547 "Tentative bus 2 radar object track/status frame. Address matches Toyota older ADAS TRACK_B_3 family; LS600h layout/scales are not confirmed.";

BO_ 549 LS600H_RADAR_TRACK_B_225: 8 XXX
 SG_ RADAR_COUNTER : 0|8@1+ (1,0) [0|255] "" XXX
 SG_ RADAR_TRACK_B_225_BYTE_1 : 8|8@1+ (1,0) [0|255] "" XXX
 SG_ RADAR_TRACK_B_225_BYTE_2 : 16|8@1+ (1,0) [0|255] "" XXX
 SG_ RADAR_TRACK_B_225_BYTE_3 : 24|8@1+ (1,0) [0|255] "" XXX
 SG_ RADAR_TRACK_B_225_BYTE_4 : 32|8@1+ (1,0) [0|255] "" XXX
 SG_ RADAR_TRACK_B_225_BYTE_5 : 40|8@1+ (1,0) [0|255] "" XXX
 SG_ RADAR_TRACK_B_225_BYTE_6 : 48|8@1+ (1,0) [0|255] "" XXX
 SG_ TENTATIVE_CHECKSUM : 56|8@1+ (1,0) [0|255] "" XXX
CM_ BO_ 549 "Tentative bus 2 radar object track/status frame. Address matches Toyota older ADAS TRACK_B_5 family; LS600h layout/scales are not confirmed.";

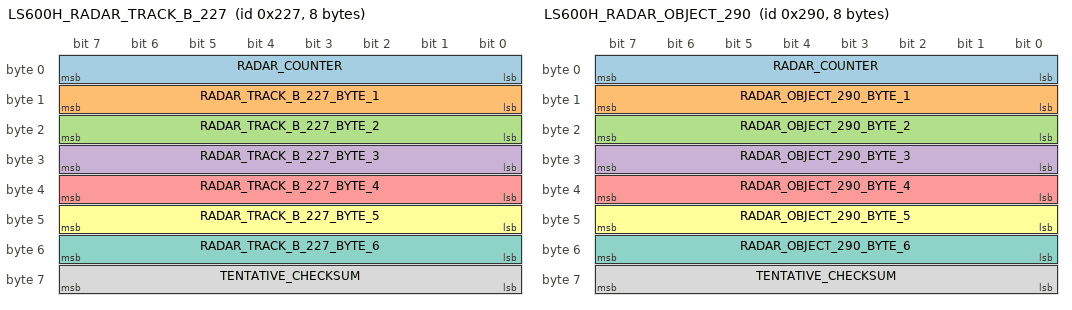
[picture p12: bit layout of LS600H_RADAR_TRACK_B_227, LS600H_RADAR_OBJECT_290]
BO_ 551 LS600H_RADAR_TRACK_B_227: 8 XXX
 SG_ RADAR_COUNTER : 0|8@1+ (1,0) [0|255] "" XXX
 SG_ RADAR_TRACK_B_227_BYTE_1 : 8|8@1+ (1,0) [0|255] "" XXX
 SG_ RADAR_TRACK_B_227_BYTE_2 : 16|8@1+ (1,0) [0|255] "" XXX
 SG_ RADAR_TRACK_B_227_BYTE_3 : 24|8@1+ (1,0) [0|255] "" XXX
 SG_ RADAR_TRACK_B_227_BYTE_4 : 32|8@1+ (1,0) [0|255] "" XXX
 SG_ RADAR_TRACK_B_227_BYTE_5 : 40|8@1+ (1,0) [0|255] "" XXX
 SG_ RADAR_TRACK_B_227_BYTE_6 : 48|8@1+ (1,0) [0|255] "" XXX
 SG_ TENTATIVE_CHECKSUM : 56|8@1+ (1,0) [0|255] "" XXX
CM_ BO_ 551 "Tentative bus 2 radar object track/status frame. Address matches Toyota older ADAS TRACK_B_7 family; LS600h layout/scales are not confirmed.";

BO_ 656 LS600H_RADAR_OBJECT_290: 8 XXX
 SG_ RADAR_COUNTER : 0|8@1+ (1,0) [0|255] "" XXX
 SG_ RADAR_OBJECT_290_BYTE_1 : 8|8@1+ (1,0) [0|255] "" XXX
 SG_ RADAR_OBJECT_290_BYTE_2 : 16|8@1+ (1,0) [0|255] "" XXX
 SG_ RADAR_OBJECT_290_BYTE_3 : 24|8@1+ (1,0) [0|255] "" XXX
 SG_ RADAR_OBJECT_290_BYTE_4 : 32|8@1+ (1,0) [0|255] "" XXX
 SG_ RADAR_OBJECT_290_BYTE_5 : 40|8@1+ (1,0) [0|255] "" XXX
 SG_ RADAR_OBJECT_290_BYTE_6 : 48|8@1+ (1,0) [0|255] "" XXX
 SG_ TENTATIVE_CHECKSUM : 56|8@1+ (1,0) [0|255] "" XXX
CM_ BO_ 656 "Tentative bus 2 radar/object frame. High-entropy payload with byte0 rolling counter and checksum-like byte7; strongly present during radar/object activity but physical signal layout is not decoded.";

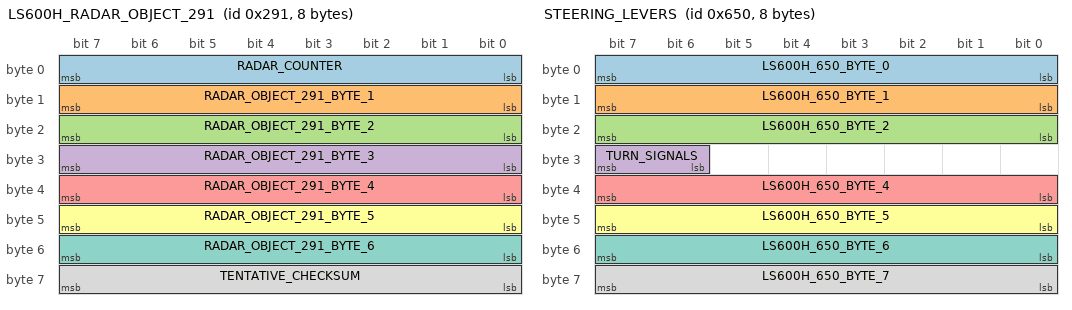
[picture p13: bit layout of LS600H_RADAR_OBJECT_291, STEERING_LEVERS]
BO_ 657 LS600H_RADAR_OBJECT_291: 8 XXX
 SG_ RADAR_COUNTER : 0|8@1+ (1,0) [0|255] "" XXX
 SG_ RADAR_OBJECT_291_BYTE_1 : 8|8@1+ (1,0) [0|255] "" XXX
 SG_ RADAR_OBJECT_291_BYTE_2 : 16|8@1+ (1,0) [0|255] "" XXX
 SG_ RADAR_OBJECT_291_BYTE_3 : 24|8@1+ (1,0) [0|255] "" XXX
 SG_ RADAR_OBJECT_291_BYTE_4 : 32|8@1+ (1,0) [0|255] "" XXX
 SG_ RADAR_OBJECT_291_BYTE_5 : 40|8@1+ (1,0) [0|255] "" XXX
 SG_ RADAR_OBJECT_291_BYTE_6 : 48|8@1+ (1,0) [0|255] "" XXX
 SG_ TENTATIVE_CHECKSUM : 56|8@1+ (1,0) [0|255] "" XXX
CM_ BO_ 657 "Tentative bus 2 radar/object frame. High-entropy payload with byte0 rolling counter and checksum-like byte7; physical signal layout is not decoded.";

BO_ 658 LS600H_RADAR_OBJECT_292: 8 XXX
 SG_ RADAR_COUNTER : 0|8@1+ (1,0) [0|255] "" XXX
 SG_ RADAR_OBJECT_292_BYTE_1 : 8|8@1+ (1,0) [0|255] "" XXX
 SG_ RADAR_OBJECT_292_BYTE_2 : 16|8@1+ (1,0) [0|255] "" XXX
 SG_ RADAR_OBJECT_292_BYTE_3 : 24|8@1+ (1,0) [0|255] "" XXX
 SG_ RADAR_OBJECT_292_BYTE_4 : 32|8@1+ (1,0) [0|255] "" XXX
 SG_ RADAR_OBJECT_292_BYTE_5 : 40|8@1+ (1,0) [0|255] "" XXX
 SG_ RADAR_OBJECT_292_BYTE_6 : 48|8@1+ (1,0) [0|255] "" XXX
 SG_ TENTATIVE_CHECKSUM : 56|8@1+ (1,0) [0|255] "" XXX
CM_ BO_ 658 "Tentative bus 2 radar/object frame. High-entropy payload with byte0 rolling counter and checksum-like byte7; physical signal layout is not decoded.";

BO_ 659 LS600H_RADAR_OBJECT_293: 8 XXX
 SG_ RADAR_COUNTER : 0|8@1+ (1,0) [0|255] "" XXX
 SG_ RADAR_OBJECT_293_BYTE_1 : 8|8@1+ (1,0) [0|255] "" XXX
 SG_ RADAR_OBJECT_293_BYTE_2 : 16|8@1+ (1,0) [0|255] "" XXX
 SG_ RADAR_OBJECT_293_BYTE_3 : 24|8@1+ (1,0) [0|255] "" XXX
 SG_ RADAR_OBJECT_293_BYTE_4 : 32|8@1+ (1,0) [0|255] "" XXX
 SG_ RADAR_OBJECT_293_BYTE_5 : 40|8@1+ (1,0) [0|255] "" XXX
 SG_ RADAR_OBJECT_293_BYTE_6 : 48|8@1+ (1,0) [0|255] "" XXX
 SG_ TENTATIVE_CHECKSUM : 56|8@1+ (1,0) [0|255] "" XXX
CM_ BO_ 659 "Tentative bus 2 radar/object frame. High-entropy payload with byte0 rolling counter and checksum-like byte7; physical signal layout is not decoded.";

BO_ 660 LS600H_RADAR_OBJECT_294: 8 XXX
 SG_ RADAR_COUNTER : 0|8@1+ (1,0) [0|255] "" XXX
 SG_ RADAR_OBJECT_294_BYTE_1 : 8|8@1+ (1,0) [0|255] "" XXX
 SG_ RADAR_OBJECT_294_BYTE_2 : 16|8@1+ (1,0) [0|255] "" XXX
 SG_ RADAR_OBJECT_294_BYTE_3 : 24|8@1+ (1,0) [0|255] "" XXX
 SG_ RADAR_OBJECT_294_BYTE_4 : 32|8@1+ (1,0) [0|255] "" XXX
 SG_ RADAR_OBJECT_294_BYTE_5 : 40|8@1+ (1,0) [0|255] "" XXX
 SG_ RADAR_OBJECT_294_BYTE_6 : 48|8@1+ (1,0) [0|255] "" XXX
 SG_ TENTATIVE_CHECKSUM : 56|8@1+ (1,0) [0|255] "" XXX
CM_ BO_ 660 "Tentative bus 2 radar/object frame. High-entropy payload with byte0 rolling counter and checksum-like byte7; physical signal layout is not decoded.";

BO_ 661 LS600H_RADAR_OBJECT_295: 8 XXX
 SG_ RADAR_COUNTER : 0|8@1+ (1,0) [0|255] "" XXX
 SG_ RADAR_OBJECT_295_BYTE_1 : 8|8@1+ (1,0) [0|255] "" XXX
 SG_ RADAR_OBJECT_295_BYTE_2 : 16|8@1+ (1,0) [0|255] "" XXX
 SG_ RADAR_OBJECT_295_BYTE_3 : 24|8@1+ (1,0) [0|255] "" XXX
 SG_ RADAR_OBJECT_295_BYTE_4 : 32|8@1+ (1,0) [0|255] "" XXX
 SG_ RADAR_OBJECT_295_BYTE_5 : 40|8@1+ (1,0) [0|255] "" XXX
 SG_ RADAR_OBJECT_295_BYTE_6 : 48|8@1+ (1,0) [0|255] "" XXX
 SG_ TENTATIVE_CHECKSUM : 56|8@1+ (1,0) [0|255] "" XXX
CM_ BO_ 661 "Tentative bus 2 radar/object frame. High-entropy payload with byte0 rolling counter and checksum-like byte7; physical signal layout is not decoded.";

BO_ 662 LS600H_RADAR_OBJECT_296: 8 XXX
 SG_ RADAR_COUNTER : 0|8@1+ (1,0) [0|255] "" XXX
 SG_ RADAR_OBJECT_296_BYTE_1 : 8|8@1+ (1,0) [0|255] "" XXX
 SG_ RADAR_OBJECT_296_BYTE_2 : 16|8@1+ (1,0) [0|255] "" XXX
 SG_ RADAR_OBJECT_296_BYTE_3 : 24|8@1+ (1,0) [0|255] "" XXX
 SG_ RADAR_OBJECT_296_BYTE_4 : 32|8@1+ (1,0) [0|255] "" XXX
 SG_ RADAR_OBJECT_296_BYTE_5 : 40|8@1+ (1,0) [0|255] "" XXX
 SG_ RADAR_OBJECT_296_BYTE_6 : 48|8@1+ (1,0) [0|255] "" XXX
 SG_ TENTATIVE_CHECKSUM : 56|8@1+ (1,0) [0|255] "" XXX
CM_ BO_ 662 "Tentative bus 2 radar/object frame. High-entropy payload with byte0 rolling counter and checksum-like byte7; physical signal layout is not decoded.";

BO_ 663 LS600H_RADAR_OBJECT_297: 8 XXX
 SG_ RADAR_COUNTER : 0|8@1+ (1,0) [0|255] "" XXX
 SG_ RADAR_OBJECT_297_BYTE_1 : 8|8@1+ (1,0) [0|255] "" XXX
 SG_ RADAR_OBJECT_297_BYTE_2 : 16|8@1+ (1,0) [0|255] "" XXX
 SG_ RADAR_OBJECT_297_BYTE_3 : 24|8@1+ (1,0) [0|255] "" XXX
 SG_ RADAR_OBJECT_297_BYTE_4 : 32|8@1+ (1,0) [0|255] "" XXX
 SG_ RADAR_OBJECT_297_BYTE_5 : 40|8@1+ (1,0) [0|255] "" XXX
 SG_ RADAR_OBJECT_297_BYTE_6 : 48|8@1+ (1,0) [0|255] "" XXX
 SG_ TENTATIVE_CHECKSUM : 56|8@1+ (1,0) [0|255] "" XXX
CM_ BO_ 663 "Tentative bus 2 radar/object frame. High-entropy payload with byte0 rolling counter and checksum-like byte7; physical signal layout is not decoded.";

BO_ 688 LS600H_RADAR_OBJECT_STATUS_2B0: 8 XXX
 SG_ RADAR_COUNTER : 0|8@1+ (1,0) [0|255] "" XXX
 SG_ RADAR_OBJECT_STATUS_2B0_BYTE_1 : 8|8@1+ (1,0) [0|255] "" XXX
 SG_ RADAR_OBJECT_STATUS_2B0_BYTE_2 : 16|8@1+ (1,0) [0|255] "" XXX
 SG_ RADAR_OBJECT_STATUS_2B0_BYTE_3 : 24|8@1+ (1,0) [0|255] "" XXX
 SG_ RADAR_OBJECT_STATUS_2B0_BYTE_4 : 32|8@1+ (1,0) [0|255] "" XXX
 SG_ RADAR_OBJECT_STATUS_2B0_BYTE_5 : 40|8@1+ (1,0) [0|255] "" XXX
 SG_ RADAR_OBJECT_STATUS_2B0_BYTE_6 : 48|8@1+ (1,0) [0|255] "" XXX
 SG_ TENTATIVE_CHECKSUM : 56|8@1+ (1,0) [0|255] "" XXX
CM_ BO_ 688 "Tentative bus 2 radar object status/score/classification frame. Changes with object/standstill events; physical signal layout is not decoded.";

BO_ 689 LS600H_RADAR_OBJECT_STATUS_2B1: 8 XXX
 SG_ RADAR_COUNTER : 0|8@1+ (1,0) [0|255] "" XXX
 SG_ RADAR_OBJECT_STATUS_2B1_BYTE_1 : 8|8@1+ (1,0) [0|255] "" XXX
 SG_ RADAR_OBJECT_STATUS_2B1_BYTE_2 : 16|8@1+ (1,0) [0|255] "" XXX
 SG_ RADAR_OBJECT_STATUS_2B1_BYTE_3 : 24|8@1+ (1,0) [0|255] "" XXX
 SG_ RADAR_OBJECT_STATUS_2B1_BYTE_4 : 32|8@1+ (1,0) [0|255] "" XXX
 SG_ RADAR_OBJECT_STATUS_2B1_BYTE_5 : 40|8@1+ (1,0) [0|255] "" XXX
 SG_ RADAR_OBJECT_STATUS_2B1_BYTE_6 : 48|8@1+ (1,0) [0|255] "" XXX
 SG_ TENTATIVE_CHECKSUM : 56|8@1+ (1,0) [0|255] "" XXX
CM_ BO_ 689 "Tentative bus 2 radar object status/score/classification frame. Changes with object/standstill events; physical signal layout is not decoded.";

BO_ 690 LS600H_RADAR_OBJECT_STATUS_2B2: 8 XXX
 SG_ RADAR_COUNTER : 0|8@1+ (1,0) [0|255] "" XXX
 SG_ RADAR_OBJECT_STATUS_2B2_BYTE_1 : 8|8@1+ (1,0) [0|255] "" XXX
 SG_ RADAR_OBJECT_STATUS_2B2_BYTE_2 : 16|8@1+ (1,0) [0|255] "" XXX
 SG_ RADAR_OBJECT_STATUS_2B2_BYTE_3 : 24|8@1+ (1,0) [0|255] "" XXX
 SG_ RADAR_OBJECT_STATUS_2B2_BYTE_4 : 32|8@1+ (1,0) [0|255] "" XXX
 SG_ RADAR_OBJECT_STATUS_2B2_BYTE_5 : 40|8@1+ (1,0) [0|255] "" XXX
 SG_ RADAR_OBJECT_STATUS_2B2_BYTE_6 : 48|8@1+ (1,0) [0|255] "" XXX
 SG_ TENTATIVE_CHECKSUM : 56|8@1+ (1,0) [0|255] "" XXX
CM_ BO_ 690 "Tentative bus 2 radar object status/score/classification frame. Changes with object/standstill events; physical signal layout is not decoded.";

BO_ 691 LS600H_RADAR_OBJECT_STATUS_2B3: 8 XXX
 SG_ RADAR_COUNTER : 0|8@1+ (1,0) [0|255] "" XXX
 SG_ RADAR_OBJECT_STATUS_2B3_BYTE_1 : 8|8@1+ (1,0) [0|255] "" XXX
 SG_ RADAR_OBJECT_STATUS_2B3_BYTE_2 : 16|8@1+ (1,0) [0|255] "" XXX
 SG_ RADAR_OBJECT_STATUS_2B3_BYTE_3 : 24|8@1+ (1,0) [0|255] "" XXX
 SG_ RADAR_OBJECT_STATUS_2B3_BYTE_4 : 32|8@1+ (1,0) [0|255] "" XXX
 SG_ RADAR_OBJECT_STATUS_2B3_BYTE_5 : 40|8@1+ (1,0) [0|255] "" XXX
 SG_ RADAR_OBJECT_STATUS_2B3_BYTE_6 : 48|8@1+ (1,0) [0|255] "" XXX
 SG_ TENTATIVE_CHECKSUM : 56|8@1+ (1,0) [0|255] "" XXX
CM_ BO_ 691 "Tentative bus 2 radar object status/score/classification frame. Changes with object/standstill events; physical signal layout is not decoded.";

BO_ 704 LS600H_RADAR_OBJECT_SUMMARY_2C0: 8 XXX
 SG_ RADAR_COUNTER : 0|8@1+ (1,0) [0|255] "" XXX
 SG_ RADAR_OBJECT_SUMMARY_2C0_BYTE_1 : 8|8@1+ (1,0) [0|255] "" XXX
 SG_ RADAR_OBJECT_SUMMARY_2C0_BYTE_2 : 16|8@1+ (1,0) [0|255] "" XXX
 SG_ RADAR_OBJECT_SUMMARY_2C0_BYTE_3 : 24|8@1+ (1,0) [0|255] "" XXX
 SG_ RADAR_OBJECT_SUMMARY_2C0_BYTE_4 : 32|8@1+ (1,0) [0|255] "" XXX
 SG_ RADAR_OBJECT_SUMMARY_2C0_BYTE_5 : 40|8@1+ (1,0) [0|255] "" XXX
 SG_ RADAR_OBJECT_SUMMARY_2C0_BYTE_6 : 48|8@1+ (1,0) [0|255] "" XXX
 SG_ TENTATIVE_CHECKSUM : 56|8@1+ (1,0) [0|255] "" XXX
CM_ BO_ 704 "Tentative lower-rate bus 2 radar/object summary/status frame. Observed near 10 Hz/2 in ACC comparison routes; byte0 is a counter and byte7 checksum-like. Physical layout is not decoded.";

BO_ 705 COMMAND: 8 XXX
 SG_ NOT_ACCELERATING_PEDAL : 3|1@1+ (1,0) [0|1] "" XXX
 SG_ ACC_PEDAL_SENSOR : 55|16@0+ (1,0) [0|65535] "" XXX
 SG_ ACC_COMMAND : 31|16@0- (1,0) [0|7] "" XXX
 SG_ ACC_PEDAL_MEAN : 15|16@0- (1,0) [0|255] "" XXX
 SG_ NEGATIVE_COMMAND_OFFSET : 47|8@0- (1,0) [0|255] "" XXX
CM_ BO_ 705 "Observed continuously on bus 2 at approximately 10 Hz in route ff528bde139e99de/0000051e--6ae54d23d9 and in ACC comparison routes. Earlier COMMAND/pedal names are still unconfirmed; latest analysis also shows this as a lower-rate radar/object/status candidate, not a proven ACC actuator command.";

BO_ 1392 LS600H_RADAR_STATUS_570: 8 XXX
 SG_ RADAR_STATUS_570_BYTE_0 : 0|8@1+ (1,0) [0|255] "" XXX
 SG_ RADAR_STATUS_570_BYTE_1 : 8|8@1+ (1,0) [0|255] "" XXX
 SG_ RADAR_STATUS_570_BYTE_2 : 16|8@1+ (1,0) [0|255] "" XXX
 SG_ RADAR_STATUS_570_BYTE_3 : 24|8@1+ (1,0) [0|255] "" XXX
 SG_ RADAR_STATUS_570_BYTE_4 : 32|8@1+ (1,0) [0|255] "" XXX
 SG_ RADAR_STATUS_570_BYTE_5 : 40|8@1+ (1,0) [0|255] "" XXX
 SG_ RADAR_STATUS_570_BYTE_6 : 48|8@1+ (1,0) [0|255] "" XXX
 SG_ TENTATIVE_CHECKSUM : 56|8@1+ (1,0) [0|255] "" XXX
CM_ BO_ 1392 "Tentative bus 2 radar/object ECU status frame. Payload states change between approach, standstill hold, and post-stop windows; exact fields are not decoded.";

BO_ 744 LS600H_2E8: 3 XXX
 SG_ LS600H_2E8_BYTE_0 : 0|8@1+ (1,0) [0|255] "" XXX
 SG_ LS600H_2E8_BYTE_1 : 8|8@1+ (1,0) [0|255] "" XXX
 SG_ LS600H_2E8_BYTE_2 : 16|8@1+ (1,0) [0|255] "" XXX
CM_ BO_ 744 "Observed continuously on bus 2 at approximately 2 Hz in the source route.";

BO_ 800 VSC1S07: 8 CGW
 SG_ FBKRLY : 6|1@0+ (1,0) [0|0] "" DS1
 SG_ FVSCM : 4|1@0+ (1,0) [0|0] "" DS1
 SG_ FVSCSFT : 3|1@0+ (1,0) [0|0] "" DS1
 SG_ FABS : 2|1@0+ (1,0) [0|0] "" DS1,FCM
 SG_ TSVSC : 1|1@0+ (1,0) [0|0] "" DS1
 SG_ FVSCL : 0|1@0+ (1,0) [0|0] "" DS1
 SG_ RQCSTBKB : 15|1@0+ (1,0) [0|0] "" Vector__XXX
 SG_ PSBSTBY : 14|1@0+ (1,0) [0|0] "" DS1
 SG_ P2BRXMK : 13|1@0+ (1,0) [0|0] "" DS1
 SG_ MCC : 11|1@0+ (1,0) [0|0] "" DS1
 SG_ RQBKB : 10|1@0+ (1,0) [0|0] "" Vector__XXX
 SG_ BRSTOP : 9|1@0+ (1,0) [0|0] "" DS1,FCM
 SG_ BRKON : 8|1@0+ (1,0) [0|0] "" DS1,FCM
 SG_ ASLP : 23|8@0- (1,0) [0|0] "deg" DS1
 SG_ BRTYPACC : 31|2@0+ (1,0) [0|0] "" DS1
 SG_ BRKABT3 : 26|1@0+ (1,0) [0|0] "" Vector__XXX
 SG_ BRKABT2 : 25|1@0+ (1,0) [0|0] "" Vector__XXX
 SG_ BRKABT1 : 24|1@0+ (1,0) [0|0] "" Vector__XXX
 SG_ GVC : 39|8@0- (0.04,0) [0|0] "m/s^2" DS1
 SG_ BRAKE_PRESSED : 42|1@0+ (1,0) [0|1] "" XXX
 SG_ XGVCINV : 43|1@0+ (1,0) [0|0] "" DS1
 SG_ S07CNT : 52|1@0+ (1,0) [0|0] "" Vector__XXX
 SG_ PCSBRSTA : 50|2@0+ (1,0) [0|0] "" DS1
 SG_ VSC07SUM : 63|8@0+ (1,0) [0|0] "" DS1,FCM
CM_ BO_ 800 "Observed continuously on bus 0 at approximately 20 Hz in the source route. BRAKE_PRESSED is the verified LS600h driver brake-pedal switch.";

BO_ 900 LS600H_384: 6 XXX
 SG_ LS600H_384_BYTE_0 : 0|8@1+ (1,0) [0|255] "" XXX
 SG_ LS600H_384_BYTE_1 : 8|8@1+ (1,0) [0|255] "" XXX
 SG_ LS600H_384_BYTE_2 : 16|8@1+ (1,0) [0|255] "" XXX
 SG_ LS600H_384_BYTE_3 : 24|8@1+ (1,0) [0|255] "" XXX
 SG_ LS600H_384_BYTE_4 : 32|8@1+ (1,0) [0|255] "" XXX
 SG_ LS600H_384_BYTE_5 : 40|8@1+ (1,0) [0|255] "" XXX
CM_ BO_ 900 "Observed continuously on bus 2 at approximately 0.3 Hz in the source route.";

BO_ 902 LS600H_386: 6 XXX
 SG_ LS600H_386_BYTE_0 : 0|8@1+ (1,0) [0|255] "" XXX
 SG_ LS600H_386_BYTE_1 : 8|8@1+ (1,0) [0|255] "" XXX
 SG_ LS600H_386_BYTE_2 : 16|8@1+ (1,0) [0|255] "" XXX
 SG_ LS600H_386_BYTE_3 : 24|8@1+ (1,0) [0|255] "" XXX
 SG_ LS600H_386_BYTE_4 : 32|8@1+ (1,0) [0|255] "" XXX
 SG_ LS600H_386_BYTE_5 : 40|8@1+ (1,0) [0|255] "" XXX
CM_ BO_ 902 "Observed continuously on bus 2 at approximately 0.3 Hz in the source route.";

BO_ 916 LS600H_394: 1 XXX
 SG_ LS600H_394_BYTE_0 : 0|8@1+ (1,0) [0|255] "" XXX
CM_ BO_ 916 "Observed continuously on bus 2 at approximately 3.3 Hz in the source route.";

BO_ 917 LS600H_395: 3 XXX
 SG_ LS600H_395_BYTE_0 : 0|8@1+ (1,0) [0|255] "" XXX
 SG_ LS600H_395_BYTE_1 : 8|8@1+ (1,0) [0|255] "" XXX
 SG_ LS600H_395_BYTE_2 : 16|8@1+ (1,0) [0|255] "" XXX
CM_ BO_ 917 "Observed continuously on bus 2 at approximately 0.5 Hz in the source route.";

BO_ 919 LS600H_397: 1 XXX
 SG_ LS600H_397_BYTE_0 : 0|8@1+ (1,0) [0|255] "" XXX
CM_ BO_ 919 "Observed continuously on bus 2 at approximately 3.3 Hz in the source route.";

BO_ 924 LS600H_39C: 1 XXX
 SG_ LS600H_39C_BYTE_0 : 0|8@1+ (1,0) [0|255] "" XXX
CM_ BO_ 924 "Observed continuously on bus 2 at approximately 1 Hz in the source route.";

BO_ 925 LS600H_39D: 1 XXX
 SG_ LS600H_39D_BYTE_0 : 0|8@1+ (1,0) [0|255] "" XXX
CM_ BO_ 925 "Observed continuously on bus 2 at approximately 1 Hz in the source route.";

BO_ 945 LS600H_3B1: 8 XXX
 SG_ LS600H_3B1_BYTE_0 : 0|8@1+ (1,0) [0|255] "" XXX
 SG_ LS600H_3B1_BYTE_1 : 8|8@1+ (1,0) [0|255] "" XXX
 SG_ LS600H_3B1_BYTE_2 : 16|8@1+ (1,0) [0|255] "" XXX
 SG_ LS600H_3B1_BYTE_3 : 24|8@1+ (1,0) [0|255] "" XXX
 SG_ LS600H_3B1_BYTE_4 : 32|8@1+ (1,0) [0|255] "" XXX
 SG_ LS600H_3B1_BYTE_5 : 40|8@1+ (1,0) [0|255] "" XXX
 SG_ LS600H_3B1_BYTE_6 : 48|8@1+ (1,0) [0|255] "" XXX
 SG_ LS600H_3B1_BYTE_7 : 56|8@1+ (1,0) [0|255] "" XXX
CM_ BO_ 945 "Observed continuously on bus 2 at approximately 1 Hz in the source route.";

BO_ 994 LS600H_3E2: 8 XXX
 SG_ LS600H_3E2_BYTE_0 : 0|8@1+ (1,0) [0|255] "" XXX
 SG_ LS600H_3E2_BYTE_1 : 8|8@1+ (1,0) [0|255] "" XXX
 SG_ LS600H_3E2_BYTE_2 : 16|8@1+ (1,0) [0|255] "" XXX
 SG_ LS600H_3E2_BYTE_3 : 24|8@1+ (1,0) [0|255] "" XXX
 SG_ LS600H_3E2_BYTE_4 : 32|8@1+ (1,0) [0|255] "" XXX
 SG_ LS600H_3E2_BYTE_5 : 40|8@1+ (1,0) [0|255] "" XXX
 SG_ LS600H_3E2_BYTE_6 : 48|8@1+ (1,0) [0|255] "" XXX
 SG_ LS600H_3E2_BYTE_7 : 56|8@1+ (1,0) [0|255] "" XXX
CM_ BO_ 994 "Observed continuously on bus 2 at approximately 2 Hz in the source route.";

BO_ 995 LS600H_3E3: 8 XXX
 SG_ LS600H_3E3_BYTE_0 : 0|8@1+ (1,0) [0|255] "" XXX
 SG_ LS600H_3E3_BYTE_1 : 8|8@1+ (1,0) [0|255] "" XXX
 SG_ LS600H_3E3_BYTE_2 : 16|8@1+ (1,0) [0|255] "" XXX
 SG_ LS600H_3E3_BYTE_3 : 24|8@1+ (1,0) [0|255] "" XXX
 SG_ LS600H_3E3_BYTE_4 : 32|8@1+ (1,0) [0|255] "" XXX
 SG_ LS600H_3E3_BYTE_5 : 40|8@1+ (1,0) [0|255] "" XXX
 SG_ LS600H_3E3_BYTE_6 : 48|8@1+ (1,0) [0|255] "" XXX
 SG_ LS600H_3E3_BYTE_7 : 56|8@1+ (1,0) [0|255] "" XXX
CM_ BO_ 995 "Observed continuously on bus 2 at approximately 2 Hz in the source route.";

BO_ 998 LS600H_3E6: 5 XXX
 SG_ LS600H_3E6_BYTE_0 : 0|8@1+ (1,0) [0|255] "" XXX
 SG_ LS600H_3E6_BYTE_1 : 8|8@1+ (1,0) [0|255] "" XXX
 SG_ LS600H_3E6_BYTE_2 : 16|8@1+ (1,0) [0|255] "" XXX
 SG_ LS600H_3E6_BYTE_3 : 24|8@1+ (1,0) [0|255] "" XXX
 SG_ LS600H_3E6_BYTE_4 : 32|8@1+ (1,0) [0|255] "" XXX
CM_ BO_ 998 "Observed continuously on bus 2 at approximately 0.3 Hz in the source route.";

BO_ 1059 LS600H_423: 1 XXX
 SG_ LS600H_423_BYTE_0 : 0|8@1+ (1,0) [0|255] "" XXX
CM_ BO_ 1059 "Observed continuously on bus 2 at approximately 1 Hz in the source route.";

BO_ 1217 LS600H_4C1: 8 XXX
 SG_ LS600H_4C1_BYTE_0 : 0|8@1+ (1,0) [0|255] "" XXX
 SG_ LS600H_4C1_BYTE_1 : 8|8@1+ (1,0) [0|255] "" XXX
 SG_ LS600H_4C1_BYTE_2 : 16|8@1+ (1,0) [0|255] "" XXX
 SG_ LS600H_4C1_BYTE_3 : 24|8@1+ (1,0) [0|255] "" XXX
 SG_ LS600H_4C1_BYTE_4 : 32|8@1+ (1,0) [0|255] "" XXX
 SG_ LS600H_4C1_BYTE_5 : 40|8@1+ (1,0) [0|255] "" XXX
 SG_ LS600H_4C1_BYTE_6 : 48|8@1+ (1,0) [0|255] "" XXX
 SG_ LS600H_4C1_BYTE_7 : 56|8@1+ (1,0) [0|255] "" XXX
CM_ BO_ 1217 "Observed continuously on bus 2 at approximately 1.1 Hz in the source route.";

BO_ 1219 LS600H_4C3: 8 XXX
 SG_ LS600H_4C3_BYTE_0 : 0|8@1+ (1,0) [0|255] "" XXX
 SG_ LS600H_4C3_BYTE_1 : 8|8@1+ (1,0) [0|255] "" XXX
 SG_ LS600H_4C3_BYTE_2 : 16|8@1+ (1,0) [0|255] "" XXX
 SG_ LS600H_4C3_BYTE_3 : 24|8@1+ (1,0) [0|255] "" XXX
 SG_ LS600H_4C3_BYTE_4 : 32|8@1+ (1,0) [0|255] "" XXX
 SG_ LS600H_4C3_BYTE_5 : 40|8@1+ (1,0) [0|255] "" XXX
 SG_ LS600H_4C3_BYTE_6 : 48|8@1+ (1,0) [0|255] "" XXX
 SG_ LS600H_4C3_BYTE_7 : 56|8@1+ (1,0) [0|255] "" XXX
CM_ BO_ 1219 "Observed continuously on bus 2 at approximately 1.1 Hz in the source route.";

BO_ 1222 LS600H_4C6: 8 XXX
 SG_ LS600H_4C6_BYTE_0 : 0|8@1+ (1,0) [0|255] "" XXX
 SG_ LS600H_4C6_BYTE_1 : 8|8@1+ (1,0) [0|255] "" XXX
 SG_ LS600H_4C6_BYTE_2 : 16|8@1+ (1,0) [0|255] "" XXX
 SG_ LS600H_4C6_BYTE_3 : 24|8@1+ (1,0) [0|255] "" XXX
 SG_ LS600H_4C6_BYTE_4 : 32|8@1+ (1,0) [0|255] "" XXX
 SG_ LS600H_4C6_BYTE_5 : 40|8@1+ (1,0) [0|255] "" XXX
 SG_ LS600H_4C6_BYTE_6 : 48|8@1+ (1,0) [0|255] "" XXX
 SG_ LS600H_4C6_BYTE_7 : 56|8@1+ (1,0) [0|255] "" XXX
CM_ BO_ 1222 "Observed continuously on bus 2 at approximately 1 Hz in the source route.";

BO_ 1223 LS600H_4C7: 8 XXX
 SG_ LS600H_4C7_BYTE_0 : 0|8@1+ (1,0) [0|255] "" XXX
 SG_ LS600H_4C7_BYTE_1 : 8|8@1+ (1,0) [0|255] "" XXX
 SG_ LS600H_4C7_BYTE_2 : 16|8@1+ (1,0) [0|255] "" XXX
 SG_ LS600H_4C7_BYTE_3 : 24|8@1+ (1,0) [0|255] "" XXX
 SG_ LS600H_4C7_BYTE_4 : 32|8@1+ (1,0) [0|255] "" XXX
 SG_ LS600H_4C7_BYTE_5 : 40|8@1+ (1,0) [0|255] "" XXX
 SG_ LS600H_4C7_BYTE_6 : 48|8@1+ (1,0) [0|255] "" XXX
 SG_ LS600H_4C7_BYTE_7 : 56|8@1+ (1,0) [0|255] "" XXX
CM_ BO_ 1223 "Observed continuously on bus 2 at approximately 1 Hz in the source route.";

BO_ 1224 LS600H_4C8: 8 XXX
 SG_ LS600H_4C8_BYTE_0 : 0|8@1+ (1,0) [0|255] "" XXX
 SG_ LS600H_4C8_BYTE_1 : 8|8@1+ (1,0) [0|255] "" XXX
 SG_ LS600H_4C8_BYTE_2 : 16|8@1+ (1,0) [0|255] "" XXX
 SG_ LS600H_4C8_BYTE_3 : 24|8@1+ (1,0) [0|255] "" XXX
 SG_ LS600H_4C8_BYTE_4 : 32|8@1+ (1,0) [0|255] "" XXX
 SG_ LS600H_4C8_BYTE_5 : 40|8@1+ (1,0) [0|255] "" XXX
 SG_ LS600H_4C8_BYTE_6 : 48|8@1+ (1,0) [0|255] "" XXX
 SG_ LS600H_4C8_BYTE_7 : 56|8@1+ (1,0) [0|255] "" XXX
CM_ BO_ 1224 "Observed continuously on bus 2 at approximately 1 Hz in the source route.";

BO_ 1226 LS600H_4CA: 8 XXX
 SG_ LS600H_4CA_BYTE_0 : 0|8@1+ (1,0) [0|255] "" XXX
 SG_ LS600H_4CA_BYTE_1 : 8|8@1+ (1,0) [0|255] "" XXX
 SG_ LS600H_4CA_BYTE_2 : 16|8@1+ (1,0) [0|255] "" XXX
 SG_ LS600H_4CA_BYTE_3 : 24|8@1+ (1,0) [0|255] "" XXX
 SG_ LS600H_4CA_BYTE_4 : 32|8@1+ (1,0) [0|255] "" XXX
 SG_ LS600H_4CA_BYTE_5 : 40|8@1+ (1,0) [0|255] "" XXX
 SG_ LS600H_4CA_BYTE_6 : 48|8@1+ (1,0) [0|255] "" XXX
 SG_ LS600H_4CA_BYTE_7 : 56|8@1+ (1,0) [0|255] "" XXX
CM_ BO_ 1226 "Observed continuously on bus 2 at approximately 1 Hz in the source route.";

BO_ 1227 LS600H_4CB: 8 XXX
 SG_ LS600H_4CB_BYTE_0 : 0|8@1+ (1,0) [0|255] "" XXX
 SG_ LS600H_4CB_BYTE_1 : 8|8@1+ (1,0) [0|255] "" XXX
 SG_ LS600H_4CB_BYTE_2 : 16|8@1+ (1,0) [0|255] "" XXX
 SG_ LS600H_4CB_BYTE_3 : 24|8@1+ (1,0) [0|255] "" XXX
 SG_ LS600H_4CB_BYTE_4 : 32|8@1+ (1,0) [0|255] "" XXX
 SG_ LS600H_4CB_BYTE_5 : 40|8@1+ (1,0) [0|255] "" XXX
 SG_ LS600H_4CB_BYTE_6 : 48|8@1+ (1,0) [0|255] "" XXX
 SG_ LS600H_4CB_BYTE_7 : 56|8@1+ (1,0) [0|255] "" XXX
CM_ BO_ 1227 "Observed continuously on bus 2 at approximately 1 Hz in the source route.";

BO_ 1236 LS600H_4D4: 8 XXX
 SG_ LS600H_4D4_BYTE_0 : 0|8@1+ (1,0) [0|255] "" XXX
 SG_ LS600H_4D4_BYTE_1 : 8|8@1+ (1,0) [0|255] "" XXX
 SG_ LS600H_4D4_BYTE_2 : 16|8@1+ (1,0) [0|255] "" XXX
 SG_ LS600H_4D4_BYTE_3 : 24|8@1+ (1,0) [0|255] "" XXX
 SG_ LS600H_4D4_BYTE_4 : 32|8@1+ (1,0) [0|255] "" XXX
 SG_ LS600H_4D4_BYTE_5 : 40|8@1+ (1,0) [0|255] "" XXX
 SG_ LS600H_4D4_BYTE_6 : 48|8@1+ (1,0) [0|255] "" XXX
 SG_ LS600H_4D4_BYTE_7 : 56|8@1+ (1,0) [0|255] "" XXX
CM_ BO_ 1236 "Observed continuously on bus 2 at approximately 0.9 Hz in the source route.";

BO_ 1241 LS600H_4D9: 8 XXX
 SG_ LS600H_4D9_BYTE_0 : 0|8@1+ (1,0) [0|255] "" XXX
 SG_ LS600H_4D9_BYTE_1 : 8|8@1+ (1,0) [0|255] "" XXX
 SG_ LS600H_4D9_BYTE_2 : 16|8@1+ (1,0) [0|255] "" XXX
 SG_ LS600H_4D9_BYTE_3 : 24|8@1+ (1,0) [0|255] "" XXX
 SG_ LS600H_4D9_BYTE_4 : 32|8@1+ (1,0) [0|255] "" XXX
 SG_ LS600H_4D9_BYTE_5 : 40|8@1+ (1,0) [0|255] "" XXX
 SG_ LS600H_4D9_BYTE_6 : 48|8@1+ (1,0) [0|255] "" XXX
 SG_ LS600H_4D9_BYTE_7 : 56|8@1+ (1,0) [0|255] "" XXX
CM_ BO_ 1241 "Observed continuously on bus 2 at approximately 0.9 Hz in the source route.";

BO_ 1254 LS600H_4E6: 8 XXX
 SG_ LS600H_4E6_BYTE_0 : 0|8@1+ (1,0) [0|255] "" XXX
 SG_ LS600H_4E6_BYTE_1 : 8|8@1+ (1,0) [0|255] "" XXX
 SG_ LS600H_4E6_BYTE_2 : 16|8@1+ (1,0) [0|255] "" XXX
 SG_ LS600H_4E6_BYTE_3 : 24|8@1+ (1,0) [0|255] "" XXX
 SG_ LS600H_4E6_BYTE_4 : 32|8@1+ (1,0) [0|255] "" XXX
 SG_ LS600H_4E6_BYTE_5 : 40|8@1+ (1,0) [0|255] "" XXX
 SG_ LS600H_4E6_BYTE_6 : 48|8@1+ (1,0) [0|255] "" XXX
 SG_ LS600H_4E6_BYTE_7 : 56|8@1+ (1,0) [0|255] "" XXX
CM_ BO_ 1254 "Observed continuously on bus 2 at approximately 0.9 Hz in the source route.";

BO_ 1255 LS600H_4E7: 8 XXX
 SG_ LS600H_4E7_BYTE_0 : 0|8@1+ (1,0) [0|255] "" XXX
 SG_ LS600H_4E7_BYTE_1 : 8|8@1+ (1,0) [0|255] "" XXX
 SG_ LS600H_4E7_BYTE_2 : 16|8@1+ (1,0) [0|255] "" XXX
 SG_ LS600H_4E7_BYTE_3 : 24|8@1+ (1,0) [0|255] "" XXX
 SG_ LS600H_4E7_BYTE_4 : 32|8@1+ (1,0) [0|255] "" XXX
 SG_ LS600H_4E7_BYTE_5 : 40|8@1+ (1,0) [0|255] "" XXX
 SG_ LS600H_4E7_BYTE_6 : 48|8@1+ (1,0) [0|255] "" XXX
 SG_ LS600H_4E7_BYTE_7 : 56|8@1+ (1,0) [0|255] "" XXX
CM_ BO_ 1255 "Observed continuously on bus 2 at approximately 0.9 Hz in the source route.";

BO_ 1572 LS600H_624: 8 XXX
 SG_ LS600H_624_BYTE_0 : 0|8@1+ (1,0) [0|255] "" XXX
 SG_ LS600H_624_BYTE_1 : 8|8@1+ (1,0) [0|255] "" XXX
 SG_ LS600H_624_BYTE_2 : 16|8@1+ (1,0) [0|255] "" XXX
 SG_ LS600H_624_BYTE_3 : 24|8@1+ (1,0) [0|255] "" XXX
 SG_ LS600H_624_BYTE_4 : 32|8@1+ (1,0) [0|255] "" XXX
 SG_ LS600H_624_BYTE_5 : 40|8@1+ (1,0) [0|255] "" XXX
 SG_ LS600H_624_BYTE_6 : 48|8@1+ (1,0) [0|255] "" XXX
 SG_ LS600H_624_BYTE_7 : 56|8@1+ (1,0) [0|255] "" XXX
CM_ BO_ 1572 "Observed continuously on bus 2 at approximately 1 Hz in the source route.";

BO_ 1616 STEERING_LEVERS: 8 XXX
 SG_ LS600H_650_BYTE_0 : 0|8@1+ (1,0) [0|255] "" XXX
 SG_ LS600H_650_BYTE_1 : 8|8@1+ (1,0) [0|255] "" XXX
 SG_ LS600H_650_BYTE_2 : 16|8@1+ (1,0) [0|255] "" XXX
 SG_ TURN_SIGNALS : 31|2@0+ (1,0) [0|3] "" XXX
 SG_ LS600H_650_BYTE_4 : 32|8@1+ (1,0) [0|255] "" XXX
 SG_ LS600H_650_BYTE_5 : 40|8@1+ (1,0) [0|255] "" XXX
 SG_ LS600H_650_BYTE_6 : 48|8@1+ (1,0) [0|255] "" XXX
 SG_ LS600H_650_BYTE_7 : 56|8@1+ (1,0) [0|255] "" XXX
CM_ BO_ 1616 "Observed continuously on bus 2 at approximately 3.3 Hz in the source route; TURN_SIGNALS also observed on buses 0/1 in route ff528bde139e99de/0000051e--6ae54d23d9.";
CM_ SG_ 1616 TURN_SIGNALS "Toyota/Lexus steering lever turn-signal state. 1 = left, 2 = right.";

CM_ "Additional sustained bus 1 traffic from route 9f2573520aa994fd/00000004--52b0dd2646.";

BO_ 55 LS600H_037: 4 XXX
 SG_ LS600H_037_BYTE_0 : 0|8@1+ (1,0) [0|255] "" XXX
 SG_ LS600H_037_BYTE_1 : 8|8@1+ (1,0) [0|255] "" XXX
 SG_ LS600H_037_BYTE_2 : 16|8@1+ (1,0) [0|255] "" XXX
 SG_ LS600H_037_BYTE_3 : 24|8@1+ (1,0) [0|255] "" XXX
CM_ BO_ 55 "Observed continuously on bus 1 at approximately 21.44 Hz in route 9f2573520aa994fd/00000004--52b0dd2646; layout not yet identified.";

BO_ 57 LS600H_039: 5 XXX
 SG_ ENGINE_TEMP : 0|8@1+ (1,0) [0|255] "degC" XXX
 SG_ LS600H_039_BYTE_1 : 8|8@1+ (1,0) [0|255] "" XXX
 SG_ LS600H_039_BYTE_2 : 16|8@1+ (1,0) [0|255] "" XXX
 SG_ LS600H_039_BYTE_3 : 24|8@1+ (1,0) [0|255] "" XXX
 SG_ LS600H_039_BYTE_4 : 32|8@1+ (1,0) [0|255] "" XXX
CM_ BO_ 57 "Observed continuously on bus 1 at approximately 21.46 Hz in route 9f2573520aa994fd/00000004--52b0dd2646; layout not yet identified.";
CM_ SG_ 57 ENGINE_TEMP "Likely engine/coolant temperature in Celsius. Observed byte 0 range was 32..88 C and settled around 85..87 C in route 9f2573520aa994fd/00000004--52b0dd2646.";

BO_ 166 BRAKE: 8 XXX
 SG_ BRAKE_AMOUNT : 7|8@0+ (1,0) [0|255] "" XXX
 SG_ BRAKE_FORCE : 23|8@0+ (40,0) [0|10200] "N" XXX
CM_ BO_ 166 "Matched by address, DLC, and plausible decoded values to _toyota_2017.dbc; observed continuously on bus 1 at approximately 14.28 Hz in route 9f2573520aa994fd/00000004--52b0dd2646.";

BO_ 176 LS600H_0B0: 8 XXX
 SG_ WHEEL_SPEED_1 : 7|16@0- (0.01,0) [-327.68|327.67] "km/h" XXX
 SG_ WHEEL_SPEED_2 : 23|16@0- (0.01,0) [-327.68|327.67] "km/h" XXX
 SG_ STATUS_1 : 39|8@0+ (1,0) [0|255] "" XXX
 SG_ STATUS_2 : 47|8@0+ (1,0) [0|255] "" XXX
 SG_ STATUS_3 : 55|8@0+ (1,0) [0|255] "" XXX
 SG_ CHECKSUM : 63|8@0+ (1,0) [0|255] "" XXX
CM_ BO_ 176 "Wheel speed pair observed continuously on bus 1 at approximately 14.41 Hz in route 9f2573520aa994fd/00000004--52b0dd2646.";
CM_ SG_ 176 WHEEL_SPEED_1 "Correlates with vehicle speed at 0.9994 using signed big-endian raw * 0.01 km/h. Exact physical wheel position is not yet identified.";
CM_ SG_ 176 WHEEL_SPEED_2 "Correlates with vehicle speed at 0.9995 using signed big-endian raw * 0.01 km/h. Exact physical wheel position is not yet identified.";
CM_ SG_ 176 CHECKSUM "Toyota checksum: (address + payload length + sum(byte0..byte6)) & 0xff.";

BO_ 178 LS600H_0B2: 8 XXX
 SG_ WHEEL_SPEED_3 : 7|16@0- (0.01,0) [-327.68|327.67] "km/h" XXX
 SG_ WHEEL_SPEED_4 : 23|16@0- (0.01,0) [-327.68|327.67] "km/h" XXX
 SG_ STATUS_1 : 39|8@0+ (1,0) [0|255] "" XXX
 SG_ STATUS_2 : 47|8@0+ (1,0) [0|255] "" XXX
 SG_ STATUS_3 : 55|8@0+ (1,0) [0|255] "" XXX
 SG_ CHECKSUM : 63|8@0+ (1,0) [0|255] "" XXX
CM_ BO_ 178 "Wheel speed pair observed continuously on bus 1 at approximately 14.41 Hz in route 9f2573520aa994fd/00000004--52b0dd2646.";
CM_ SG_ 178 WHEEL_SPEED_3 "Correlates with vehicle speed at 0.9996 using signed big-endian raw * 0.01 km/h. Exact physical wheel position is not yet identified.";
CM_ SG_ 178 WHEEL_SPEED_4 "Correlates with vehicle speed at 0.9995 using signed big-endian raw * 0.01 km/h. Exact physical wheel position is not yet identified.";
CM_ SG_ 178 CHECKSUM "Toyota checksum: (address + payload length + sum(byte0..byte6)) & 0xff.";

BO_ 288 LS600H_120: 7 XXX
 SG_ LS600H_120_BYTE_0 : 0|8@1+ (1,0) [0|255] "" XXX
 SG_ LS600H_120_BYTE_1 : 8|8@1+ (1,0) [0|255] "" XXX
 SG_ LS600H_120_BYTE_2 : 16|8@1+ (1,0) [0|255] "" XXX
 SG_ LS600H_120_BYTE_3 : 24|8@1+ (1,0) [0|255] "" XXX
 SG_ LS600H_120_BYTE_4 : 32|8@1+ (1,0) [0|255] "" XXX
 SG_ LS600H_120_BYTE_5 : 40|8@1+ (1,0) [0|255] "" XXX
 SG_ LS600H_120_BYTE_6 : 48|8@1+ (1,0) [0|255] "" XXX
CM_ BO_ 288 "Observed continuously on bus 1 at approximately 10.72 Hz in route 9f2573520aa994fd/00000004--52b0dd2646; layout not yet identified.";

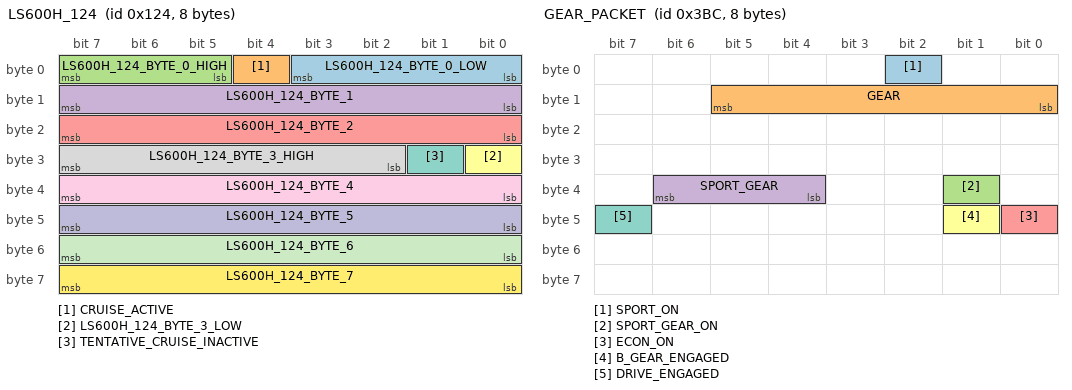
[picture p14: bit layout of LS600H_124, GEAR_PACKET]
BO_ 292 LS600H_124: 8 XXX
 SG_ LS600H_124_BYTE_0_LOW : 0|4@1+ (1,0) [0|15] "" XXX
 SG_ CRUISE_ACTIVE : 4|1@1+ (1,0) [0|1] "" XXX
 SG_ LS600H_124_BYTE_0_HIGH : 5|3@1+ (1,0) [0|7] "" XXX
 SG_ LS600H_124_BYTE_1 : 8|8@1+ (1,0) [0|255] "" XXX
 SG_ LS600H_124_BYTE_2 : 16|8@1+ (1,0) [0|255] "" XXX
 SG_ LS600H_124_BYTE_3_LOW : 24|1@1+ (1,0) [0|1] "" XXX
 SG_ TENTATIVE_CRUISE_INACTIVE : 25|1@1+ (1,0) [0|1] "" XXX
 SG_ LS600H_124_BYTE_3_HIGH : 26|6@1+ (1,0) [0|63] "" XXX
 SG_ LS600H_124_BYTE_4 : 32|8@1+ (1,0) [0|255] "" XXX
 SG_ LS600H_124_BYTE_5 : 40|8@1+ (1,0) [0|255] "" XXX
 SG_ LS600H_124_BYTE_6 : 48|8@1+ (1,0) [0|255] "" XXX
 SG_ LS600H_124_BYTE_7 : 56|8@1+ (1,0) [0|255] "" XXX
CM_ BO_ 292 "Observed continuously on bus 1 at approximately 5.5 Hz across LS600h routes. Cruise/status frame; not an ACC command frame.";
CM_ SG_ 292 CRUISE_ACTIVE "Cruise control active state, byte 0 mask 0x10. Confirmed against multiple cruise on/off windows.";
CM_ SG_ 292 TENTATIVE_CRUISE_INACTIVE "Unconfirmed raw byte3 mask 0x02. Strong inverse correlation with CRUISE_ACTIVE in available routes.";

BO_ 294 LS600H_126: 8 XXX
 SG_ LS600H_126_BYTE_0 : 0|8@1+ (1,0) [0|255] "" XXX
 SG_ TENTATIVE_DECEL_STATUS_1 : 8|1@1+ (1,0) [0|1] "" XXX
 SG_ TENTATIVE_DECEL_STATUS_2 : 9|1@1+ (1,0) [0|1] "" XXX
 SG_ TENTATIVE_DECEL_STATUS_3 : 10|1@1+ (1,0) [0|1] "" XXX
 SG_ LS600H_126_BYTE_1_BIT3 : 11|1@1+ (1,0) [0|1] "" XXX
 SG_ TENTATIVE_DECEL_STATUS_4 : 12|1@1+ (1,0) [0|1] "" XXX
 SG_ LS600H_126_BYTE_1_BIT5 : 13|1@1+ (1,0) [0|1] "" XXX
 SG_ TENTATIVE_BRKON_STATUS : 14|1@1+ (1,0) [0|1] "" XXX
 SG_ LS600H_126_BYTE_1_BIT7 : 15|1@1+ (1,0) [0|1] "" XXX
 SG_ LS600H_126_BYTE_2_LOW : 16|7@1+ (1,0) [0|127] "" XXX
 SG_ TENTATIVE_DECEL_STATUS_5 : 23|1@1+ (1,0) [0|1] "" XXX
 SG_ LS600H_126_BYTE_3_LOW : 24|6@1+ (1,0) [0|63] "" XXX
 SG_ GAS_PEDAL_PRESSED : 30|1@1+ (1,0) [0|1] "" XXX
 SG_ LS600H_126_BYTE_3_HIGH : 31|1@1+ (1,0) [0|1] "" XXX
 SG_ LS600H_126_BYTE_4 : 32|8@1+ (1,0) [0|255] "" XXX
 SG_ LS600H_126_BYTE_5 : 40|8@1+ (1,0) [0|255] "" XXX
 SG_ LS600H_126_BYTE_6_LOW : 48|7@1+ (1,0) [0|127] "" XXX
 SG_ TENTATIVE_CRUISE_ACCEL_ALLOWED : 55|1@1+ (1,0) [0|1] "" XXX
 SG_ LS600H_126_BYTE_7 : 56|8@1+ (1,0) [0|255] "" XXX
CM_ BO_ 294 "Observed continuously on bus 1 at approximately 10.7 Hz across LS600h routes. Pedal/status frame; not an ACC command frame. Some bits are lead/status-correlated in limited data but are not named yet.";
CM_ SG_ 294 GAS_PEDAL_PRESSED "Accelerator pedal pressed state, byte 3 mask 0x40.";
CM_ SG_ 294 TENTATIVE_DECEL_STATUS_1 "Unconfirmed raw byte1 mask 0x01. Correlates with decel/BRKON windows in available routes.";
CM_ SG_ 294 TENTATIVE_DECEL_STATUS_2 "Unconfirmed raw byte1 mask 0x02. Correlates with decel/BRKON windows in available routes.";
CM_ SG_ 294 TENTATIVE_DECEL_STATUS_3 "Unconfirmed raw byte1 mask 0x04. Correlates with decel/BRKON windows in available routes.";
CM_ SG_ 294 TENTATIVE_DECEL_STATUS_4 "Unconfirmed raw byte1 mask 0x10. Correlates with decel/BRKON windows in available routes.";
CM_ SG_ 294 TENTATIVE_BRKON_STATUS "Unconfirmed raw byte1 mask 0x40. Strongest correlation with VSC1S07 BRKON in available routes.";
CM_ SG_ 294 TENTATIVE_DECEL_STATUS_5 "Unconfirmed raw byte2 mask 0x80. Correlates with decel/BRKON windows in available routes.";
CM_ SG_ 294 TENTATIVE_CRUISE_ACCEL_ALLOWED "Unconfirmed raw byte6 mask 0x80. Usually high during cruise and low during BRKON/decel windows.";

BO_ 296 LS600H_128: 8 XXX
 SG_ LS600H_128_BYTE_0 : 0|8@1+ (1,0) [0|255] "" XXX
 SG_ LS600H_128_BYTE_1 : 8|8@1+ (1,0) [0|255] "" XXX
 SG_ LS600H_128_BYTE_2 : 16|8@1+ (1,0) [0|255] "" XXX
 SG_ LS600H_128_BYTE_3 : 24|8@1+ (1,0) [0|255] "" XXX
 SG_ LS600H_128_BYTE_4 : 32|8@1+ (1,0) [0|255] "" XXX
 SG_ LS600H_128_BYTE_5 : 40|8@1+ (1,0) [0|255] "" XXX
 SG_ LS600H_128_BYTE_6 : 48|8@1+ (1,0) [0|255] "" XXX
 SG_ LS600H_128_BYTE_7 : 56|8@1+ (1,0) [0|255] "" XXX
CM_ BO_ 296 "Observed continuously on bus 1 at approximately 10.72 Hz in route 9f2573520aa994fd/00000004--52b0dd2646; layout not yet identified.";

BO_ 560 BRAKE_2: 7 XXX
 SG_ BRAKE_PRESSED : 26|1@0+ (1,0) [0|1] "" XXX
CM_ BO_ 560 "Matched by address, DLC, and plausible decoded values to _toyota_2017.dbc; observed continuously on bus 1 at approximately 7.21 Hz in route 9f2573520aa994fd/00000004--52b0dd2646.";

BO_ 566 LS600H_236: 4 XXX
 SG_ LS600H_236_BYTE_0 : 0|8@1+ (1,0) [0|255] "" XXX
 SG_ LS600H_236_BYTE_1 : 8|8@1+ (1,0) [0|255] "" XXX
 SG_ LS600H_236_BYTE_2 : 16|8@1+ (1,0) [0|255] "" XXX
 SG_ LS600H_236_BYTE_3 : 24|8@1+ (1,0) [0|255] "" XXX
CM_ BO_ 566 "Observed continuously on bus 1 at approximately 7.14 Hz in route 9f2573520aa994fd/00000004--52b0dd2646; layout not yet identified.";

BO_ 580 LS600H_244: 7 XXX
 SG_ LS600H_244_BYTE_0 : 0|8@1+ (1,0) [0|255] "" XXX
 SG_ LS600H_244_BYTE_1 : 8|8@1+ (1,0) [0|255] "" XXX
 SG_ LS600H_244_BYTE_2 : 16|8@1+ (1,0) [0|255] "" XXX
 SG_ LS600H_244_BYTE_3 : 24|8@1+ (1,0) [0|255] "" XXX
 SG_ LS600H_244_BYTE_4 : 32|8@1+ (1,0) [0|255] "" XXX
 SG_ LS600H_244_BYTE_5 : 40|8@1+ (1,0) [0|255] "" XXX
 SG_ LS600H_244_BYTE_6 : 48|8@1+ (1,0) [0|255] "" XXX
CM_ BO_ 580 "Observed continuously on bus 1 at approximately 7.46 Hz in route 9f2573520aa994fd/00000004--52b0dd2646; layout not yet identified.";

BO_ 610 EPS_STATUS: 5 EPS
 SG_ IPAS_STATE : 3|4@0+ (1,0) [0|15] "" XXX
 SG_ LKA_STATE : 31|7@0+ (1,0) [0|127] "" XXX
 SG_ TYPE : 24|1@0+ (1,0) [0|1] "" XXX
 SG_ CHECKSUM : 39|8@0+ (1,0) [0|255] "" XXX
CM_ BO_ 610 "Matched by address, DLC, and plausible decoded values to toyota_new_mc_pt.dbc; observed continuously on bus 1 at approximately 4.40 Hz in route 9f2573520aa994fd/00000004--52b0dd2646.";

BO_ 620 LS600H_26C: 5 XXX
 SG_ LS600H_26C_BYTE_0 : 0|8@1+ (1,0) [0|255] "" XXX
 SG_ LS600H_26C_BYTE_1 : 8|8@1+ (1,0) [0|255] "" XXX
 SG_ LS600H_26C_BYTE_2 : 16|8@1+ (1,0) [0|255] "" XXX
 SG_ LS600H_26C_BYTE_3 : 24|8@1+ (1,0) [0|255] "" XXX
 SG_ LS600H_26C_BYTE_4 : 32|8@1+ (1,0) [0|255] "" XXX
CM_ BO_ 620 "Observed continuously on bus 1 at approximately 7.33 Hz in route 9f2573520aa994fd/00000004--52b0dd2646; layout not yet identified.";

BO_ 640 LS600H_280: 8 XXX
 SG_ LS600H_280_BYTE_0 : 0|8@1+ (1,0) [0|255] "" XXX
 SG_ LS600H_280_BYTE_1 : 8|8@1+ (1,0) [0|255] "" XXX
 SG_ LS600H_280_BYTE_2 : 16|8@1+ (1,0) [0|255] "" XXX
 SG_ LS600H_280_BYTE_3 : 24|8@1+ (1,0) [0|255] "" XXX
 SG_ LS600H_280_BYTE_4 : 32|8@1+ (1,0) [0|255] "" XXX
 SG_ LS600H_280_BYTE_5 : 40|8@1+ (1,0) [0|255] "" XXX
 SG_ LS600H_280_BYTE_6 : 48|8@1+ (1,0) [0|255] "" XXX
 SG_ LS600H_280_BYTE_7 : 56|8@1+ (1,0) [0|255] "" XXX
CM_ BO_ 640 "Observed continuously on bus 1 at approximately 5.49 Hz in route 9f2573520aa994fd/00000004--52b0dd2646; layout not yet identified.";

BO_ 710 LS600H_2C6: 3 CAN_Master
 SG_ BRAKE_PRESSED : 1|1@1+ (1,0) [0|1] "" STM32G474_HRR
 SG_ LS600H_2C6_BYTE_1 : 8|8@1+ (1,0) [0|255] "" XXX
 SG_ LS600H_2C6_BYTE_2 : 16|8@1+ (1,0) [0|255] "" XXX
CM_ BO_ 710 "Brake interlock input watched by HRR CANCTR. Panda forwards the unchanged LS600h bus 1 0x2C6 frame to bus 2 because this ID was absent from the supplied Radar bus capture. BRAKE_PRESSED is byte0 bit1. A missing or stale frame, or a fresh frame with BRAKE_PRESSED=1, sets SVEC DELTA to 0 and drives REL and RELE off; torque and relay commands are ignored until a fresh not-pressed frame arrives.";
CM_ SG_ 710 BRAKE_PRESSED "When 1 in a fresh 0x2C6 frame, HRR CANCTR disengages torque output and opens REL/RELE. Missing or stale 0x2C6 also keeps the interlock active.";

BO_ 810 LS600H_32A: 2 XXX
 SG_ LS600H_32A_BYTE_0 : 0|8@1+ (1,0) [0|255] "" XXX
 SG_ LS600H_32A_BYTE_1 : 8|8@1+ (1,0) [0|255] "" XXX
CM_ BO_ 810 "Observed continuously on bus 1 at approximately 3.57 Hz in route 9f2573520aa994fd/00000004--52b0dd2646; layout not yet identified.";

BO_ 812 LS600H_32C: 2 XXX
 SG_ LS600H_32C_BYTE_0 : 0|8@1+ (1,0) [0|255] "" XXX
 SG_ LS600H_32C_BYTE_1 : 8|8@1+ (1,0) [0|255] "" XXX
CM_ BO_ 812 "Observed continuously on bus 1 at approximately 3.67 Hz in route 9f2573520aa994fd/00000004--52b0dd2646; layout not yet identified.";

BO_ 845 LS600H_34D: 7 XXX
 SG_ LS600H_34D_BYTE_0 : 0|8@1+ (1,0) [0|255] "" XXX
 SG_ LS600H_34D_BYTE_1 : 8|8@1+ (1,0) [0|255] "" XXX
 SG_ LS600H_34D_BYTE_2 : 16|8@1+ (1,0) [0|255] "" XXX
 SG_ LS600H_34D_BYTE_3 : 24|8@1+ (1,0) [0|255] "" XXX
 SG_ LS600H_34D_BYTE_4 : 32|8@1+ (1,0) [0|255] "" XXX
 SG_ LS600H_34D_BYTE_5 : 40|8@1+ (1,0) [0|255] "" XXX
 SG_ LS600H_34D_BYTE_6 : 48|8@1+ (1,0) [0|255] "" XXX
CM_ BO_ 845 "Observed continuously on bus 1 at approximately 3.46 Hz in route 9f2573520aa994fd/00000004--52b0dd2646; layout not yet identified.";

BO_ 905 LS600H_389: 3 XXX
 SG_ LS600H_389_BYTE_0 : 0|8@1+ (1,0) [0|255] "" XXX
 SG_ LS600H_389_BYTE_1 : 8|8@1+ (1,0) [0|255] "" XXX
 SG_ LS600H_389_BYTE_2 : 16|8@1+ (1,0) [0|255] "" XXX
CM_ BO_ 905 "Observed continuously on bus 1 at approximately 0.18 Hz in route 9f2573520aa994fd/00000004--52b0dd2646; layout not yet identified.";

BO_ 918 LS600H_396: 7 XXX
 SG_ LS600H_396_BYTE_0 : 0|8@1+ (1,0) [0|255] "" XXX
 SG_ LS600H_396_BYTE_1 : 8|8@1+ (1,0) [0|255] "" XXX
 SG_ LS600H_396_BYTE_2 : 16|8@1+ (1,0) [0|255] "" XXX
 SG_ LS600H_396_BYTE_3 : 24|8@1+ (1,0) [0|255] "" XXX
 SG_ LS600H_396_BYTE_4 : 32|8@1+ (1,0) [0|255] "" XXX
 SG_ LS600H_396_BYTE_5 : 40|8@1+ (1,0) [0|255] "" XXX
 SG_ LS600H_396_BYTE_6 : 48|8@1+ (1,0) [0|255] "" XXX
CM_ BO_ 918 "Observed continuously on bus 1 at approximately 0.18 Hz in route 9f2573520aa994fd/00000004--52b0dd2646; layout not yet identified.";

BO_ 929 LS600H_3A1: 8 XXX
 SG_ LS600H_3A1_BYTE_0 : 0|8@1+ (1,0) [0|255] "" XXX
 SG_ LS600H_3A1_BYTE_1 : 8|8@1+ (1,0) [0|255] "" XXX
 SG_ LS600H_3A1_BYTE_2 : 16|8@1+ (1,0) [0|255] "" XXX
 SG_ LS600H_3A1_BYTE_3 : 24|8@1+ (1,0) [0|255] "" XXX
 SG_ LS600H_3A1_BYTE_4 : 32|8@1+ (1,0) [0|255] "" XXX
 SG_ LS600H_3A1_BYTE_5 : 40|8@1+ (1,0) [0|255] "" XXX
 SG_ LS600H_3A1_BYTE_6 : 48|8@1+ (1,0) [0|255] "" XXX
 SG_ LS600H_3A1_BYTE_7 : 56|8@1+ (1,0) [0|255] "" XXX
CM_ BO_ 929 "Observed continuously on bus 1 at approximately 0.18 Hz in route 9f2573520aa994fd/00000004--52b0dd2646; layout not yet identified.";

BO_ 944 LS600H_3B0: 6 XXX
 SG_ LS600H_3B0_BYTE_0 : 0|8@1+ (1,0) [0|255] "" XXX
 SG_ LS600H_3B0_BYTE_1 : 8|8@1+ (1,0) [0|255] "" XXX
 SG_ LS600H_3B0_BYTE_2 : 16|8@1+ (1,0) [0|255] "" XXX
 SG_ LS600H_3B0_BYTE_3 : 24|8@1+ (1,0) [0|255] "" XXX
 SG_ LS600H_3B0_BYTE_4 : 32|8@1+ (1,0) [0|255] "" XXX
 SG_ LS600H_3B0_BYTE_5 : 40|8@1+ (1,0) [0|255] "" XXX
CM_ BO_ 944 "Observed continuously on bus 1 at approximately 0.18 Hz in route 9f2573520aa994fd/00000004--52b0dd2646; layout not yet identified.";

BO_ 948 LS600H_3B4: 8 XXX
 SG_ LS600H_3B4_BYTE_0 : 0|8@1+ (1,0) [0|255] "" XXX
 SG_ LS600H_3B4_BYTE_1 : 8|8@1+ (1,0) [0|255] "" XXX
 SG_ LS600H_3B4_BYTE_2 : 16|8@1+ (1,0) [0|255] "" XXX
 SG_ LS600H_3B4_BYTE_3 : 24|8@1+ (1,0) [0|255] "" XXX
 SG_ LS600H_3B4_BYTE_4 : 32|8@1+ (1,0) [0|255] "" XXX
 SG_ LS600H_3B4_BYTE_5 : 40|8@1+ (1,0) [0|255] "" XXX
 SG_ LS600H_3B4_BYTE_6 : 48|8@1+ (1,0) [0|255] "" XXX
 SG_ LS600H_3B4_BYTE_7 : 56|8@1+ (1,0) [0|255] "" XXX
CM_ BO_ 948 "Observed continuously on bus 1 at approximately 0.19 Hz in route 9f2573520aa994fd/00000004--52b0dd2646; layout not yet identified.";

BO_ 954 LS600H_3BA: 1 XXX
 SG_ LS600H_3BA_BYTE_0 : 0|8@1+ (1,0) [0|255] "" XXX
CM_ BO_ 954 "Observed continuously on bus 1 at approximately 0.18 Hz in route 9f2573520aa994fd/00000004--52b0dd2646; layout not yet identified.";

BO_ 956 GEAR_PACKET: 8 XXX
 SG_ SPORT_ON : 2|1@0+ (1,0) [0|1] "" XXX
 SG_ GEAR : 13|6@0+ (1,0) [0|63] "" XXX
 SG_ SPORT_GEAR_ON : 33|1@0+ (1,0) [0|1] "" XXX
 SG_ SPORT_GEAR : 38|3@0+ (1,0) [0|7] "" XXX
 SG_ ECON_ON : 40|1@0+ (1,0) [0|1] "" XXX
 SG_ B_GEAR_ENGAGED : 41|1@0+ (1,0) [0|1] "" XXX
 SG_ DRIVE_ENGAGED : 47|1@0+ (1,0) [0|1] "" XXX
CM_ BO_ 956 "Matched by address, DLC, and plausible decoded values to _toyota_2017.dbc; observed continuously on bus 1 at approximately 0.17 Hz in route 9f2573520aa994fd/00000004--52b0dd2646.";

BO_ 968 LS600H_3C8: 6 XXX
 SG_ LS600H_3C8_BYTE_0 : 0|8@1+ (1,0) [0|255] "" XXX
 SG_ LS600H_3C8_BYTE_1 : 8|8@1+ (1,0) [0|255] "" XXX
 SG_ LS600H_3C8_BYTE_2 : 16|8@1+ (1,0) [0|255] "" XXX
 SG_ LS600H_3C8_BYTE_3 : 24|8@1+ (1,0) [0|255] "" XXX
 SG_ LS600H_3C8_BYTE_4 : 32|8@1+ (1,0) [0|255] "" XXX
 SG_ LS600H_3C8_BYTE_5 : 40|8@1+ (1,0) [0|255] "" XXX
CM_ BO_ 968 "Observed continuously on bus 1 at approximately 2.68 Hz in route 9f2573520aa994fd/00000004--52b0dd2646; layout not yet identified.";

BO_ 975 LS600H_3CF: 5 XXX
 SG_ LS600H_3CF_BYTE_0 : 0|8@1+ (1,0) [0|255] "" XXX
 SG_ LS600H_3CF_BYTE_1 : 8|8@1+ (1,0) [0|255] "" XXX
 SG_ LS600H_3CF_BYTE_2 : 16|8@1+ (1,0) [0|255] "" XXX
 SG_ LS600H_3CF_BYTE_3 : 24|8@1+ (1,0) [0|255] "" XXX
 SG_ LS600H_3CF_BYTE_4 : 32|8@1+ (1,0) [0|255] "" XXX
CM_ BO_ 975 "Observed continuously on bus 1 at approximately 1.34 Hz in route 9f2573520aa994fd/00000004--52b0dd2646; layout not yet identified.";

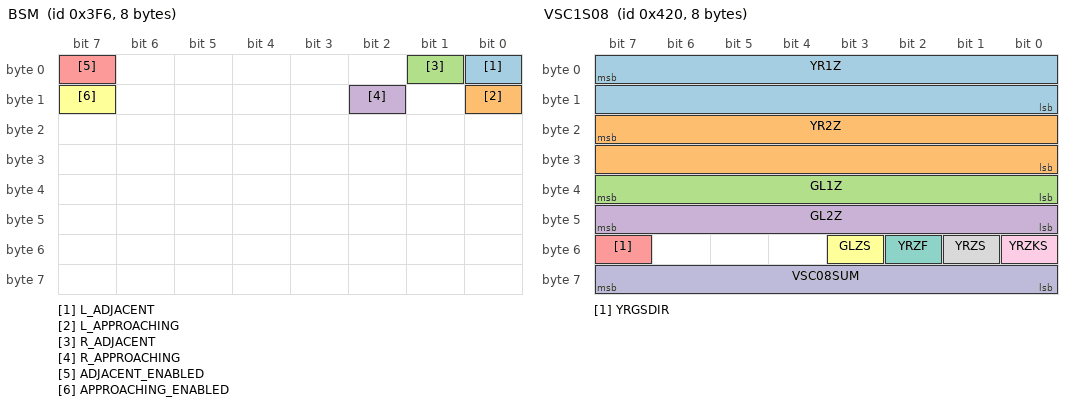
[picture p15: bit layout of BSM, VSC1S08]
BO_ 1014 BSM: 8 XXX
 SG_ L_ADJACENT : 0|1@0+ (1,0) [0|1] "" XXX
 SG_ L_APPROACHING : 8|1@0+ (1,0) [0|1] "" XXX
 SG_ R_ADJACENT : 1|1@0+ (1,0) [0|1] "" XXX
 SG_ R_APPROACHING : 10|1@0+ (1,0) [0|1] "" XXX
 SG_ ADJACENT_ENABLED : 7|1@0+ (1,0) [0|1] "" XXX
 SG_ APPROACHING_ENABLED : 15|1@0+ (1,0) [0|1] "" XXX
CM_ BO_ 1014 "Matched by address, DLC, and plausible decoded values to toyota_nodsu_pt.dbc; observed continuously on bus 1 at approximately 0.18 Hz in route 9f2573520aa994fd/00000004--52b0dd2646.";

BO_ 1017 LS600H_3F9: 8 XXX
 SG_ LS600H_3F9_BYTE_0 : 0|8@1+ (1,0) [0|255] "" XXX
 SG_ LS600H_3F9_BYTE_1 : 8|8@1+ (1,0) [0|255] "" XXX
 SG_ LS600H_3F9_BYTE_2 : 16|8@1+ (1,0) [0|255] "" XXX
 SG_ LS600H_3F9_BYTE_3 : 24|8@1+ (1,0) [0|255] "" XXX
 SG_ LS600H_3F9_BYTE_4 : 32|8@1+ (1,0) [0|255] "" XXX
 SG_ LS600H_3F9_BYTE_5 : 40|8@1+ (1,0) [0|255] "" XXX
 SG_ LS600H_3F9_BYTE_6 : 48|8@1+ (1,0) [0|255] "" XXX
 SG_ LS600H_3F9_BYTE_7 : 56|8@1+ (1,0) [0|255] "" XXX
CM_ BO_ 1017 "Observed continuously on bus 1 at approximately 0.70 Hz in route 9f2573520aa994fd/00000004--52b0dd2646; layout not yet identified.";

BO_ 1056 VSC1S08: 8 CGW
 SG_ YR1Z : 7|16@0- (1,0) [0|0] "rad/s" DS1,FCM,MAV
 SG_ YR2Z : 23|16@0- (1,0) [0|0] "rad/s" DS1,FCM,MAV
 SG_ GL1Z : 39|8@0- (0.0359,0) [0|0] "m/s^2" DS1,FCM,KSS,MAV,SCS
 SG_ GL2Z : 47|8@0- (0.0359,0) [0|0] "m/s^2" DS1,FCM,KSS,MAV,SCS
 SG_ YRGSDIR : 55|1@0+ (1,0) [0|0] "" DS1,FCM,KSS,SCS
 SG_ GLZS : 51|1@0+ (1,0) [0|0] "" DS1,FCM,KSS,MAV,SCS
 SG_ YRZF : 50|1@0+ (1,0) [0|0] "" DS1,FCM,MAV
 SG_ YRZS : 49|1@0+ (1,0) [0|0] "" DS1,FCM,MAV
 SG_ YRZKS : 48|1@0+ (1,0) [0|0] "" DS1,FCM,MAV
 SG_ VSC08SUM : 63|8@0+ (1,0) [0|0] "" DS1,FCM,MAV
CM_ BO_ 1056 "Matched by address, DLC, and plausible decoded values to _toyota_2017.dbc; observed continuously on bus 1 at approximately 0.17 Hz in route 9f2573520aa994fd/00000004--52b0dd2646.";

BO_ 1112 LS600H_458: 8 XXX
 SG_ LS600H_458_BYTE_0 : 0|8@1+ (1,0) [0|255] "" XXX
 SG_ LS600H_458_BYTE_1 : 8|8@1+ (1,0) [0|255] "" XXX
 SG_ LS600H_458_BYTE_2 : 16|8@1+ (1,0) [0|255] "" XXX
 SG_ LS600H_458_BYTE_3 : 24|8@1+ (1,0) [0|255] "" XXX
 SG_ LS600H_458_BYTE_4 : 32|8@1+ (1,0) [0|255] "" XXX
 SG_ LS600H_458_BYTE_5 : 40|8@1+ (1,0) [0|255] "" XXX
 SG_ LS600H_458_BYTE_6 : 48|8@1+ (1,0) [0|255] "" XXX
 SG_ LS600H_458_BYTE_7 : 56|8@1+ (1,0) [0|255] "" XXX
CM_ BO_ 1112 "Observed continuously on bus 1 at approximately 0.18 Hz in route 9f2573520aa994fd/00000004--52b0dd2646; layout not yet identified.";

BO_ 1187 LS600H_4A3: 8 XXX
 SG_ LS600H_4A3_BYTE_0 : 0|8@1+ (1,0) [0|255] "" XXX
 SG_ LS600H_4A3_BYTE_1 : 8|8@1+ (1,0) [0|255] "" XXX
 SG_ LS600H_4A3_BYTE_2 : 16|8@1+ (1,0) [0|255] "" XXX
 SG_ LS600H_4A3_BYTE_3 : 24|8@1+ (1,0) [0|255] "" XXX
 SG_ LS600H_4A3_BYTE_4 : 32|8@1+ (1,0) [0|255] "" XXX
 SG_ LS600H_4A3_BYTE_5 : 40|8@1+ (1,0) [0|255] "" XXX
 SG_ LS600H_4A3_BYTE_6 : 48|8@1+ (1,0) [0|255] "" XXX
 SG_ LS600H_4A3_BYTE_7 : 56|8@1+ (1,0) [0|255] "" XXX
CM_ BO_ 1187 "Observed continuously on bus 1 at approximately 0.35 Hz in route 9f2573520aa994fd/00000004--52b0dd2646; layout not yet identified.";

BO_ 1193 LS600H_4A9: 8 XXX
 SG_ LS600H_4A9_BYTE_0 : 0|8@1+ (1,0) [0|255] "" XXX
 SG_ LS600H_4A9_BYTE_1 : 8|8@1+ (1,0) [0|255] "" XXX
 SG_ LS600H_4A9_BYTE_2 : 16|8@1+ (1,0) [0|255] "" XXX
 SG_ LS600H_4A9_BYTE_3 : 24|8@1+ (1,0) [0|255] "" XXX
 SG_ LS600H_4A9_BYTE_4 : 32|8@1+ (1,0) [0|255] "" XXX
 SG_ LS600H_4A9_BYTE_5 : 40|8@1+ (1,0) [0|255] "" XXX
 SG_ LS600H_4A9_BYTE_6 : 48|8@1+ (1,0) [0|255] "" XXX
 SG_ LS600H_4A9_BYTE_7 : 56|8@1+ (1,0) [0|255] "" XXX
CM_ BO_ 1193 "Observed continuously on bus 1 at approximately 0.35 Hz in route 9f2573520aa994fd/00000004--52b0dd2646; layout not yet identified.";

BO_ 1194 LS600H_4AA: 8 XXX
 SG_ LS600H_4AA_BYTE_0 : 0|8@1+ (1,0) [0|255] "" XXX
 SG_ LS600H_4AA_BYTE_1 : 8|8@1+ (1,0) [0|255] "" XXX
 SG_ LS600H_4AA_BYTE_2 : 16|8@1+ (1,0) [0|255] "" XXX
 SG_ LS600H_4AA_BYTE_3 : 24|8@1+ (1,0) [0|255] "" XXX
 SG_ LS600H_4AA_BYTE_4 : 32|8@1+ (1,0) [0|255] "" XXX
 SG_ LS600H_4AA_BYTE_5 : 40|8@1+ (1,0) [0|255] "" XXX
 SG_ LS600H_4AA_BYTE_6 : 48|8@1+ (1,0) [0|255] "" XXX
 SG_ LS600H_4AA_BYTE_7 : 56|8@1+ (1,0) [0|255] "" XXX
CM_ BO_ 1194 "Observed continuously on bus 1 at approximately 0.35 Hz in route 9f2573520aa994fd/00000004--52b0dd2646; layout not yet identified.";

BO_ 1195 LS600H_4AB: 8 XXX
 SG_ LS600H_4AB_BYTE_0 : 0|8@1+ (1,0) [0|255] "" XXX
 SG_ LS600H_4AB_BYTE_1 : 8|8@1+ (1,0) [0|255] "" XXX
 SG_ LS600H_4AB_BYTE_2 : 16|8@1+ (1,0) [0|255] "" XXX
 SG_ LS600H_4AB_BYTE_3 : 24|8@1+ (1,0) [0|255] "" XXX
 SG_ LS600H_4AB_BYTE_4 : 32|8@1+ (1,0) [0|255] "" XXX
 SG_ LS600H_4AB_BYTE_5 : 40|8@1+ (1,0) [0|255] "" XXX
 SG_ LS600H_4AB_BYTE_6 : 48|8@1+ (1,0) [0|255] "" XXX
 SG_ LS600H_4AB_BYTE_7 : 56|8@1+ (1,0) [0|255] "" XXX
CM_ BO_ 1195 "Observed continuously on bus 1 at approximately 0.35 Hz in route 9f2573520aa994fd/00000004--52b0dd2646; layout not yet identified.";

BO_ 1221 LS600H_4C5: 8 XXX
 SG_ LS600H_4C5_BYTE_0 : 0|8@1+ (1,0) [0|255] "" XXX
 SG_ LS600H_4C5_BYTE_1 : 8|8@1+ (1,0) [0|255] "" XXX
 SG_ LS600H_4C5_BYTE_2 : 16|8@1+ (1,0) [0|255] "" XXX
 SG_ LS600H_4C5_BYTE_3 : 24|8@1+ (1,0) [0|255] "" XXX
 SG_ LS600H_4C5_BYTE_4 : 32|8@1+ (1,0) [0|255] "" XXX
 SG_ LS600H_4C5_BYTE_5 : 40|8@1+ (1,0) [0|255] "" XXX
 SG_ LS600H_4C5_BYTE_6 : 48|8@1+ (1,0) [0|255] "" XXX
 SG_ LS600H_4C5_BYTE_7 : 56|8@1+ (1,0) [0|255] "" XXX
CM_ BO_ 1221 "Observed continuously on bus 1 at approximately 0.18 Hz in route 9f2573520aa994fd/00000004--52b0dd2646; layout not yet identified.";

BO_ 1228 LS600H_4CC: 8 XXX
 SG_ LS600H_4CC_BYTE_0 : 0|8@1+ (1,0) [0|255] "" XXX
 SG_ LS600H_4CC_BYTE_1 : 8|8@1+ (1,0) [0|255] "" XXX
 SG_ LS600H_4CC_BYTE_2 : 16|8@1+ (1,0) [0|255] "" XXX
 SG_ LS600H_4CC_BYTE_3 : 24|8@1+ (1,0) [0|255] "" XXX
 SG_ LS600H_4CC_BYTE_4 : 32|8@1+ (1,0) [0|255] "" XXX
 SG_ LS600H_4CC_BYTE_5 : 40|8@1+ (1,0) [0|255] "" XXX
 SG_ LS600H_4CC_BYTE_6 : 48|8@1+ (1,0) [0|255] "" XXX
 SG_ LS600H_4CC_BYTE_7 : 56|8@1+ (1,0) [0|255] "" XXX
CM_ BO_ 1228 "Observed continuously on bus 1 at approximately 0.17 Hz in route 9f2573520aa994fd/00000004--52b0dd2646; layout not yet identified.";

BO_ 1232 LS600H_4D0: 8 XXX
 SG_ LS600H_4D0_BYTE_0 : 0|8@1+ (1,0) [0|255] "" XXX
 SG_ LS600H_4D0_BYTE_1 : 8|8@1+ (1,0) [0|255] "" XXX
 SG_ LS600H_4D0_BYTE_2 : 16|8@1+ (1,0) [0|255] "" XXX
 SG_ LS600H_4D0_BYTE_3 : 24|8@1+ (1,0) [0|255] "" XXX
 SG_ LS600H_4D0_BYTE_4 : 32|8@1+ (1,0) [0|255] "" XXX
 SG_ LS600H_4D0_BYTE_5 : 40|8@1+ (1,0) [0|255] "" XXX
 SG_ LS600H_4D0_BYTE_6 : 48|8@1+ (1,0) [0|255] "" XXX
 SG_ LS600H_4D0_BYTE_7 : 56|8@1+ (1,0) [0|255] "" XXX
CM_ BO_ 1232 "Observed continuously on bus 1 at approximately 0.17 Hz in route 9f2573520aa994fd/00000004--52b0dd2646; layout not yet identified.";

BO_ 1237 LS600H_4D5: 8 XXX
 SG_ LS600H_4D5_BYTE_0 : 0|8@1+ (1,0) [0|255] "" XXX
 SG_ LS600H_4D5_BYTE_1 : 8|8@1+ (1,0) [0|255] "" XXX
 SG_ LS600H_4D5_BYTE_2 : 16|8@1+ (1,0) [0|255] "" XXX
 SG_ LS600H_4D5_BYTE_3 : 24|8@1+ (1,0) [0|255] "" XXX
 SG_ LS600H_4D5_BYTE_4 : 32|8@1+ (1,0) [0|255] "" XXX
 SG_ LS600H_4D5_BYTE_5 : 40|8@1+ (1,0) [0|255] "" XXX
 SG_ LS600H_4D5_BYTE_6 : 48|8@1+ (1,0) [0|255] "" XXX
 SG_ LS600H_4D5_BYTE_7 : 56|8@1+ (1,0) [0|255] "" XXX
CM_ BO_ 1237 "Observed continuously on bus 1 at approximately 0.14 Hz in route 9f2573520aa994fd/00000004--52b0dd2646; layout not yet identified.";

BO_ 1552 BODY_CONTROL_STATE_2: 8 XXX
 SG_ UI_SPEED : 23|8@0+ (1,0) [0|255] "" XXX
 SG_ METER_SLIDER_BRIGHTNESS_PCT : 30|7@0+ (1,0) [12|100] "%" XXX
 SG_ METER_SLIDER_LOW_BRIGHTNESS : 37|1@0+ (1,0) [0|1] "" XXX
 SG_ METER_SLIDER_DIMMED : 38|1@0+ (1,0) [0|1] "" XXX
 SG_ UNITS : 63|3@0+ (1,0) [1|4] "" XXX
CM_ BO_ 1552 "Matched by address, DLC, and plausible decoded values to _toyota_2017.dbc; observed continuously on bus 1 at approximately 0.36 Hz in route 9f2573520aa994fd/00000004--52b0dd2646.";

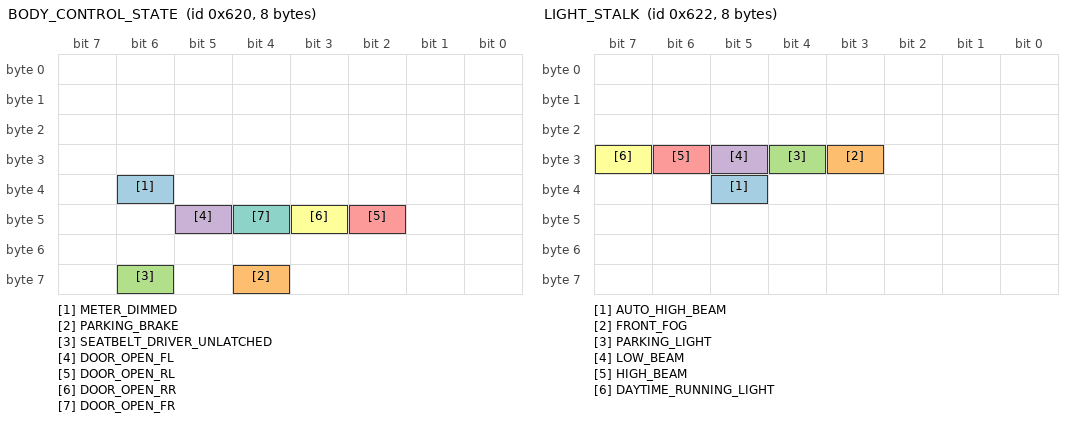
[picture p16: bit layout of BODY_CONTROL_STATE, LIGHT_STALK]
BO_ 1568 BODY_CONTROL_STATE: 8 XXX
 SG_ METER_DIMMED : 38|1@0+ (1,0) [0|1] "" XXX
 SG_ PARKING_BRAKE : 60|1@0+ (1,0) [0|1] "" XXX
 SG_ SEATBELT_DRIVER_UNLATCHED : 62|1@0+ (1,0) [0|1] "" XXX
 SG_ DOOR_OPEN_FL : 45|1@0+ (1,0) [0|1] "" XXX
 SG_ DOOR_OPEN_RL : 42|1@0+ (1,0) [0|1] "" XXX
 SG_ DOOR_OPEN_RR : 43|1@0+ (1,0) [0|1] "" XXX
 SG_ DOOR_OPEN_FR : 44|1@0+ (1,0) [0|1] "" XXX
CM_ BO_ 1568 "Matched by address, DLC, and plausible decoded values to _toyota_2017.dbc; observed continuously on bus 1 at approximately 0.60 Hz in route 9f2573520aa994fd/00000004--52b0dd2646.";

BO_ 1570 LIGHT_STALK: 8 SCM
 SG_ AUTO_HIGH_BEAM : 37|1@0+ (1,0) [0|1] "" XXX
 SG_ FRONT_FOG : 27|1@0+ (1,0) [0|1] "" XXX
 SG_ PARKING_LIGHT : 28|1@0+ (1,0) [0|1] "" XXX
 SG_ LOW_BEAM : 29|1@0+ (1,0) [0|1] "" XXX
 SG_ HIGH_BEAM : 30|1@0+ (1,0) [0|1] "" XXX
 SG_ DAYTIME_RUNNING_LIGHT : 31|1@0+ (1,0) [0|1] "" XXX
CM_ BO_ 1570 "Matched by address, DLC, and plausible decoded values to _toyota_2017.dbc; observed continuously on bus 1 at approximately 0.18 Hz in route 9f2573520aa994fd/00000004--52b0dd2646.";

BO_ 1602 LS600H_642: 8 XXX
 SG_ LS600H_642_BYTE_0 : 0|8@1+ (1,0) [0|255] "" XXX
 SG_ LS600H_642_BYTE_1 : 8|8@1+ (1,0) [0|255] "" XXX
 SG_ LS600H_642_BYTE_2 : 16|8@1+ (1,0) [0|255] "" XXX
 SG_ LS600H_642_BYTE_3 : 24|8@1+ (1,0) [0|255] "" XXX
 SG_ LS600H_642_BYTE_4 : 32|8@1+ (1,0) [0|255] "" XXX
 SG_ LS600H_642_BYTE_5 : 40|8@1+ (1,0) [0|255] "" XXX
 SG_ LS600H_642_BYTE_6 : 48|8@1+ (1,0) [0|255] "" XXX
 SG_ LS600H_642_BYTE_7 : 56|8@1+ (1,0) [0|255] "" XXX
CM_ BO_ 1602 "Observed continuously on bus 1 at approximately 0.18 Hz in route 9f2573520aa994fd/00000004--52b0dd2646; layout not yet identified.";

BO_ 1744 LS600H_6D0: 8 XXX
 SG_ LS600H_6D0_BYTE_0 : 0|8@1+ (1,0) [0|255] "" XXX
 SG_ LS600H_6D0_BYTE_1 : 8|8@1+ (1,0) [0|255] "" XXX
 SG_ LS600H_6D0_BYTE_2 : 16|8@1+ (1,0) [0|255] "" XXX
 SG_ LS600H_6D0_BYTE_3 : 24|8@1+ (1,0) [0|255] "" XXX
 SG_ LS600H_6D0_BYTE_4 : 32|8@1+ (1,0) [0|255] "" XXX
 SG_ LS600H_6D0_BYTE_5 : 40|8@1+ (1,0) [0|255] "" XXX
 SG_ LS600H_6D0_BYTE_6 : 48|8@1+ (1,0) [0|255] "" XXX
 SG_ LS600H_6D0_BYTE_7 : 56|8@1+ (1,0) [0|255] "" XXX
CM_ BO_ 1744 "Observed continuously on bus 1 at approximately 1.77 Hz in route 9f2573520aa994fd/00000004--52b0dd2646; layout not yet identified.";

BO_ 1752 LS600H_6D8: 8 XXX
 SG_ LS600H_6D8_BYTE_0 : 0|8@1+ (1,0) [0|255] "" XXX
 SG_ LS600H_6D8_BYTE_1 : 8|8@1+ (1,0) [0|255] "" XXX
 SG_ LS600H_6D8_BYTE_2 : 16|8@1+ (1,0) [0|255] "" XXX
 SG_ LS600H_6D8_BYTE_3 : 24|8@1+ (1,0) [0|255] "" XXX
 SG_ LS600H_6D8_BYTE_4 : 32|8@1+ (1,0) [0|255] "" XXX
 SG_ LS600H_6D8_BYTE_5 : 40|8@1+ (1,0) [0|255] "" XXX
 SG_ LS600H_6D8_BYTE_6 : 48|8@1+ (1,0) [0|255] "" XXX
 SG_ LS600H_6D8_BYTE_7 : 56|8@1+ (1,0) [0|255] "" XXX
CM_ BO_ 1752 "Observed continuously on bus 1 at approximately 0.18 Hz in route 9f2573520aa994fd/00000004--52b0dd2646; layout not yet identified.";

BO_ 1539 CANCTR_SvecConfigCmd: 8 CAN_Master
 SG_ Config_Command : 0|8@1+ (1,0) [1|20] "" STM32G474_HRR
 SG_ Config_Value : 8|32@1+ (1,0) [0|4294967295] "" STM32G474_HRR
 SG_ Config_Key : 40|8@1+ (1,0) [165|165] "" STM32G474_HRR
 SG_ Config_Reserved : 48|8@1+ (1,0) [0|0] "" STM32G474_HRR
 SG_ Config_Checksum : 56|8@1+ (1,0) [0|255] "" STM32G474_HRR
CM_ SG_ 1539 Config_Value "Raw u32 transport. Interpret commands 3, 8, 10, and 11..19 as signed two's-complement int32; commands 3 and 8 use 0.1 degree/bit, command 10 uses 0.01 degree/bit, and commands 11..19 use Q20 scaling.";
CM_ BO_ 1539 "One-shot HRR configuration. Commands 1..3 and 8 apply active SVEC settings without writing flash; command 9 appends one CRC-protected record containing the current DLY, ANGLE_OFFSET, and SVEC_ZERO_OFFSET. Command 4 starts a safe calibration session with a nonzero u32 token; command 5 finishes using that same token; command 6 aborts using that token or value zero for forced recovery; command 7 selects legacy (0) or calibrated (1) angles. Command 8 sets signed SVEC_ZERO_OFFSET in 0.1 degrees. Command 10 supplies a non-persistent manual signed steering reference in 0.01 degrees. Commands 11..18 stage signed row-major IN then OU 2x2 matrix coefficients in Q20; command 19 stages signed phase-per-steer Q20; command 20 packs sample_count in bits0..15, RMS error tenths in bits16..23, and max error tenths in bits24..31. Config_Key must be 0xA5, Config_Reserved zero, and checksum CRC-8/poly-0x07 over ID low, ID high, bytes0..6.";

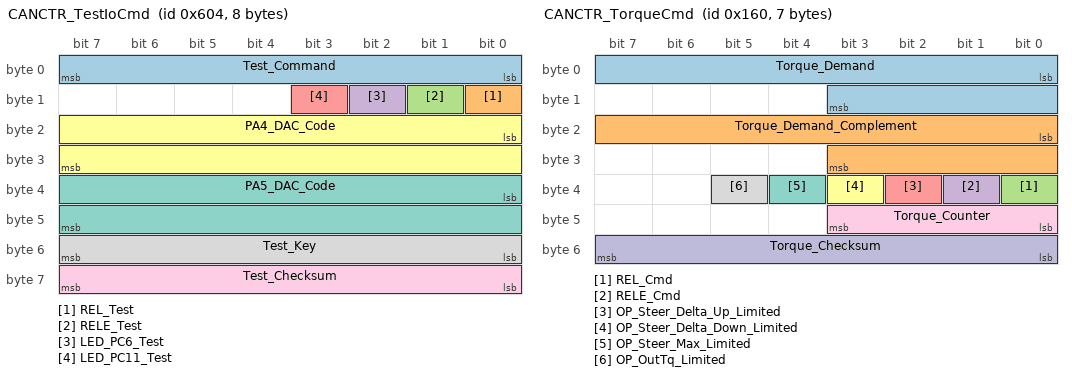
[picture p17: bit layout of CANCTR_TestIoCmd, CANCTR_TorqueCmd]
BO_ 1540 CANCTR_TestIoCmd: 8 CAN_Master
 SG_ Test_Command : 0|8@1+ (1,0) [0|4] "" STM32G474_HRR
 SG_ REL_Test : 8|1@1+ (1,0) [0|1] "" STM32G474_HRR
 SG_ RELE_Test : 9|1@1+ (1,0) [0|1] "" STM32G474_HRR
 SG_ LED_PC6_Test : 10|1@1+ (1,0) [0|1] "" STM32G474_HRR
 SG_ LED_PC11_Test : 11|1@1+ (1,0) [0|1] "" STM32G474_HRR
 SG_ PA4_DAC_Code : 16|16@1+ (1,0) [0|4095] "code" STM32G474_HRR
 SG_ PA5_DAC_Code : 32|16@1+ (1,0) [0|4095] "code" STM32G474_HRR
 SG_ Test_Key : 48|8@1+ (1,0) [165|165] "" STM32G474_HRR
 SG_ Test_Checksum : 56|8@1+ (1,0) [0|255] "" STM32G474_HRR
CM_ BO_ 1540 "Keyed static-output test command. Commands 1..4 stop live TIM6/DMA output and take test ownership; command 1 applies digital flags only, commands 2 and 3 update PA4 or PA5 respectively, and command 4 updates both raw 12-bit DAC codes. All commands 1..4 apply relay and logical LED flags; PC11 active-low polarity is handled by firmware. These relay flags deliberately bypass normal brake/torque interlocks but remain blocked during resolver calibration. Commands 1..4 must refresh the 1000 ms deadman; expiry or command 0 safely opens relays, releases LEDs and DACs, and restores CANCTR. Test_Key must be 0xA5 and Test_Checksum is CRC-8/poly-0x07 over ID low, ID high, and bytes0..6.";

BO_ 352 CANCTR_TorqueCmd: 7 CAN_Master
 SG_ Torque_Demand : 0|12@1- (1,0) [-800|800] "Ncm" STM32G474_HRR
 SG_ Torque_Demand_Complement : 16|12@1+ (1,0) [0|4095] "raw12" STM32G474_HRR
 SG_ REL_Cmd : 32|1@1+ (1,0) [0|1] "" STM32G474_HRR
 SG_ RELE_Cmd : 33|1@1+ (1,0) [0|1] "" STM32G474_HRR
 SG_ OP_Steer_Delta_Up_Limited : 34|1@1+ (1,0) [0|1] "" STM32G474_HRR
 SG_ OP_Steer_Delta_Down_Limited : 35|1@1+ (1,0) [0|1] "" STM32G474_HRR
 SG_ OP_Steer_Max_Limited : 36|1@1+ (1,0) [0|1] "" STM32G474_HRR
 SG_ OP_OutTq_Limited : 37|1@1+ (1,0) [0|1] "" STM32G474_HRR
 SG_ Torque_Counter : 40|4@1+ (1,0) [0|15] "" STM32G474_HRR
 SG_ Torque_Checksum : 48|8@1+ (1,0) [0|255] "" STM32G474_HRR
CM_ BO_ 352 "Desired EPS output torque command. Assigned to 0x160 because it was absent from the supplied LS600h Radar bus capture. Torque_Demand uses the low 12 bits of bytes0..1 as a signed Ncm demand, Torque_Demand_Complement is the 12-bit ones-complement in bytes2..3, byte4 carries relay commands plus host limiter bits, Torque_Counter is byte5 bits0..3, and Torque_Checksum is CRC-8 over id_lo, id_hi, and bytes0..5 with polynomial 0x07 and init 0x00. CANCTR maps +/-800 Ncm to a full -/+13.5-degree applied rotation span about persistent SVEC_ZERO_OFFSET. The effective rotation can reach +/-27.0 degrees. Missing or stale commands activate the 250 ms torque interlock, reset SVEC delta, and open REL/RELE.";
CM_ SG_ 352 Torque_Demand "Signed desired EPS output torque demand in Ncm. HRR CANCTR applies inverse-sign scaling: +800 Ncm produces -13.5 degrees of applied SVEC rotation relative to SVEC_ZERO_OFFSET.";
CM_ SG_ 352 Torque_Demand_Complement "12-bit ones-complement redundancy for Torque_Demand, encoded as Torque_Demand raw12 XOR 0x0FFF.";
CM_ SG_ 352 Torque_Counter "4-bit rolling counter carried in byte5 bits0..3.";
CM_ SG_ 352 Torque_Checksum "8-bit CRC over id_lo, id_hi, and bytes0..5 using polynomial 0x07 and init 0x00.";

BO_ 1584 CANCTR_AdcStatus: 8 STM32G474_HRR
 SG_ INSN_Raw : 0|16@1+ (1,0) [0|4095] "code" CAN_Master
 SG_ INCS_Raw : 16|16@1+ (1,0) [0|4095] "code" CAN_Master
 SG_ OUCS_Raw : 32|16@1+ (1,0) [0|4095] "code" CAN_Master
 SG_ OUSN_Raw : 48|16@1+ (1,0) [0|4095] "code" CAN_Master
CM_ BO_ 1584 "Raw 12-bit conversion codes: INSN=PB15, INCS=PB13, OUCS=PA1, OUSN=PA2.";

BO_ 1585 CANCTR_IOStatus: 5 STM32G474_HRR
 SG_ DAC1_Code : 0|16@1+ (1,0) [0|4095] "code" CAN_Master
 SG_ DAC2_Code : 16|16@1+ (1,0) [0|4095] "code" CAN_Master
 SG_ REL_State : 32|1@1+ (1,0) [0|1] "" CAN_Master
 SG_ RELE_State : 33|1@1+ (1,0) [0|1] "" CAN_Master
 SG_ RC_Minus : 34|1@1+ (1,0) [0|1] "" CAN_Master
 SG_ RC_Plus : 35|1@1+ (1,0) [0|1] "" CAN_Master
CM_ BO_ 1585 "Reported DAC output codes plus relay and RC input states. RC_Minus maps PB4, RC_Plus maps PB1.";
CM_ SG_ 1585 RC_Minus "Digital input PB4 / RC-.";
CM_ SG_ 1585 RC_Plus "Digital input PB1 / RC+.";

BO_ 1586 HRR_AngleStatus: 8 STM32G474_HRR
 SG_ SVEC_Delta : 0|16@1- (0.1,0) [-40|40] "deg" CAN_Master
 SG_ Emulated_Torque : 16|16@1- (1,0) [-1600|1600] "Ncm" CAN_Master
 SG_ OU_Angle : 32|16@1+ (0.1,0) [0|179.9] "deg" CAN_Master
 SG_ IN_Angle : 48|16@1+ (0.1,0) [0|179.9] "deg" CAN_Master
CM_ BO_ 1586 "HRR control summary. SVEC_Delta is the effective resolver-vector rotation after SVEC_ZERO_OFFSET, reported in the CANCTR torque-command sign convention opposite its applied rotation. Emulated_Torque is the raw-rotation equivalent using 800 Ncm per 13.5 degrees and can reach +/-1600 Ncm; requested torque remains limited to +/-800 Ncm about the calibrated zero. OU_Angle is measured from OUSN/OUCS and IN_Angle from INSN/INCS; consult HRR_StateStatus validity bits before using either angle.";

BO_ 1587 CANCTR_VoltageStatus: 8 STM32G474_HRR
 SG_ INSN : 0|16@1- (0.001,0) [-32.768|32.767] "V" CAN_Master
 SG_ INCS : 16|16@1- (0.001,0) [-32.768|32.767] "V" CAN_Master
 SG_ OUCS : 32|16@1- (0.001,0) [-32.768|32.767] "V" CAN_Master
 SG_ OUSN : 48|16@1- (0.001,0) [-32.768|32.767] "V" CAN_Master
CM_ BO_ 1587 "Signed resolver signal voltages relative to TQG after op-amp scaling, sent in millivolts and scaled here to volts.";

BO_ 1588 HRR_StateStatus: 8 STM32G474_HRR
 SG_ REL_Measured : 0|1@1+ (1,0) [0|1] "" CAN_Master
 SG_ RELE_Measured : 1|1@1+ (1,0) [0|1] "" CAN_Master
 SG_ OU_Angle_Valid : 2|1@1+ (1,0) [0|1] "" CAN_Master
 SG_ IN_Angle_Valid : 3|1@1+ (1,0) [0|1] "" CAN_Master
 SG_ Brake_Frame_Seen : 4|1@1+ (1,0) [0|1] "" CAN_Master
 SG_ Brake_Frame_Fresh : 5|1@1+ (1,0) [0|1] "" CAN_Master
 SG_ Brake_Pressed : 6|1@1+ (1,0) [0|1] "" CAN_Master
 SG_ Brake_Interlock : 7|1@1+ (1,0) [0|1] "" CAN_Master
 SG_ Torque_Frame_Accepted : 8|1@1+ (1,0) [0|1] "" CAN_Master
 SG_ SVEC_Centers_Valid : 9|1@1+ (1,0) [0|1] "" CAN_Master
 SG_ Mirror_Running : 10|1@1+ (1,0) [0|1] "" CAN_Master
 SG_ SVEC_Guard_Enabled : 11|1@1+ (1,0) [0|1] "" CAN_Master
 SG_ SVEC_Guard_Angles_Valid : 12|1@1+ (1,0) [0|1] "" CAN_Master
 SG_ CANCTR_Enabled : 13|1@1+ (1,0) [0|1] "" CAN_Master
 SG_ Torque_Frame_Fresh : 14|1@1+ (1,0) [0|1] "" CAN_Master
 SG_ Torque_Interlock : 15|1@1+ (1,0) [0|1] "" CAN_Master
 SG_ Angle_Delta : 16|16@1- (0.1,0) [-90|90] "deg" CAN_Master
 SG_ Brake_Frame_Age : 32|16@1+ (1,0) [0|65534] "ms" CAN_Master
 SG_ Torque_Frame_Age : 48|16@1+ (1,0) [0|65534] "ms" CAN_Master
CM_ BO_ 1588 "HRR safety and measurement state. Brake_Frame_Age is 65535 when no brake frame has been seen; Torque_Frame_Age is 65535 when no valid torque frame has been accepted. Angle_Delta is the signed shortest modulo-180 OU_Angle minus IN_Angle minus ANGLE_OFFSET difference and is valid only when both angle-valid bits are set.";

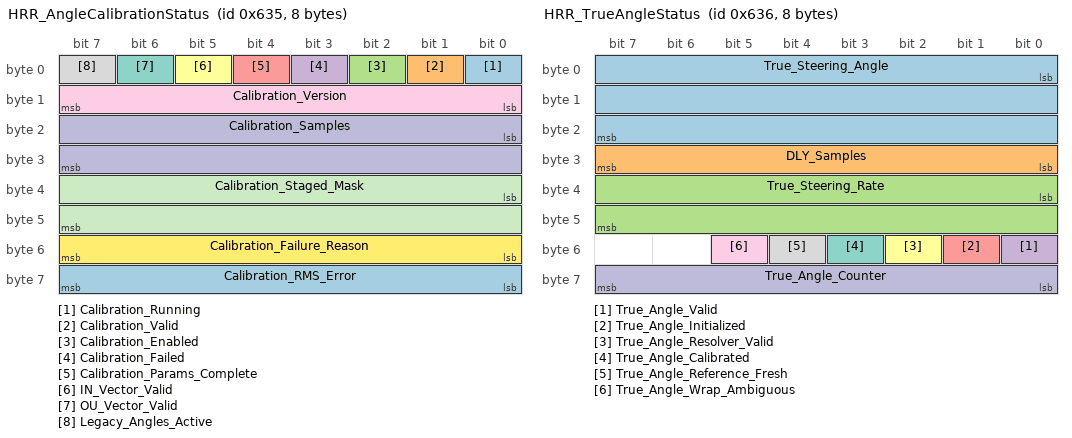
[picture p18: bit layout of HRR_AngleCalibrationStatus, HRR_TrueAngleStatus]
BO_ 1589 HRR_AngleCalibrationStatus: 8 STM32G474_HRR
 SG_ Calibration_Running : 0|1@1+ (1,0) [0|1] "" CAN_Master
 SG_ Calibration_Valid : 1|1@1+ (1,0) [0|1] "" CAN_Master
 SG_ Calibration_Enabled : 2|1@1+ (1,0) [0|1] "" CAN_Master
 SG_ Calibration_Failed : 3|1@1+ (1,0) [0|1] "" CAN_Master
 SG_ Calibration_Params_Complete : 4|1@1+ (1,0) [0|1] "" CAN_Master
 SG_ IN_Vector_Valid : 5|1@1+ (1,0) [0|1] "" CAN_Master
 SG_ OU_Vector_Valid : 6|1@1+ (1,0) [0|1] "" CAN_Master
 SG_ Legacy_Angles_Active : 7|1@1+ (1,0) [0|1] "" CAN_Master
 SG_ Calibration_Version : 8|8@1+ (1,0) [0|255] "" CAN_Master
 SG_ Calibration_Samples : 16|16@1+ (1,0) [0|65535] "samples" CAN_Master
 SG_ Calibration_Staged_Mask : 32|16@1+ (1,0) [0|1023] "" CAN_Master
 SG_ Calibration_Failure_Reason : 48|8@1+ (1,0) [0|25] "" CAN_Master
 SG_ Calibration_RMS_Error : 56|8@1+ (0.1,0) [0|25.5] "deg" CAN_Master
CM_ BO_ 1589 "Resolver calibration protocol v2 status. Staged mask bits 0..7 correspond to commands 11..18, bit8 to command 19, and bit9 to command 20. A complete fit requires mask 0x03FF, at least 100 samples, RMS error <=1.5 degrees, and maximum error <=5.0 degrees. Failure reasons: 0 none, 1 generic unsafe, 2 session, 3 incomplete, 4 coefficient, 5 fit, 6 NVM, 7 timeout, 8..14 and 19..20 specific failed safety precondition, 21..25 retained flash-reset step.";

BO_ 1590 HRR_TrueAngleStatus: 8 STM32G474_HRR
 SG_ True_Steering_Angle : 0|24@1- (0.01,0) [-83886.08|83886.07] "deg" CAN_Master
 SG_ DLY_Samples : 24|8@1+ (1,0) [0|127] "samples" CAN_Master
 SG_ True_Steering_Rate : 32|16@1- (0.1,0) [-3276.8|3276.7] "deg/s" CAN_Master
 SG_ True_Angle_Valid : 48|1@1+ (1,0) [0|1] "" CAN_Master
 SG_ True_Angle_Initialized : 49|1@1+ (1,0) [0|1] "" CAN_Master
 SG_ True_Angle_Resolver_Valid : 50|1@1+ (1,0) [0|1] "" CAN_Master
 SG_ True_Angle_Calibrated : 51|1@1+ (1,0) [0|1] "" CAN_Master
 SG_ True_Angle_Reference_Fresh : 52|1@1+ (1,0) [0|1] "" CAN_Master
 SG_ True_Angle_Wrap_Ambiguous : 53|1@1+ (1,0) [0|1] "" CAN_Master
 SG_ True_Angle_Counter : 56|8@1+ (1,0) [0|255] "" CAN_Master
CM_ BO_ 1590 "High-resolution absolute steering measurement from the CAL2-corrected IN resolver vector. Angle is valid only after a fresh, consistent 0x25 reference anchors the modulo-180 sector. Invalid gap, delta, or derived rate clears initialization; a fresh reference permits automatic re-anchoring. Legacy or disabled calibration never sets True_Angle_Valid.";

BO_ 1591 HRR_ResolverVectorStatus: 8 STM32G474_HRR
 SG_ IN_Cos_RMS : 0|16@1- (1,0) [-32768|32767] "code_rms" CAN_Master
 SG_ IN_Sin_Signed_RMS : 16|16@1- (1,0) [-32768|32767] "code_rms" CAN_Master
 SG_ OU_Cos_RMS : 32|16@1- (1,0) [-32768|32767] "code_rms" CAN_Master
 SG_ OU_Sin_Signed_RMS : 48|16@1- (1,0) [-32768|32767] "code_rms" CAN_Master
CM_ BO_ 1591 "Uncalibrated signed RMS/covariance vectors used before atan2. Cos RMS is nonnegative; the sine RMS sign is selected from centered sine/cosine covariance. Host calibration fits 2x2 Q20 matrices to these values.";

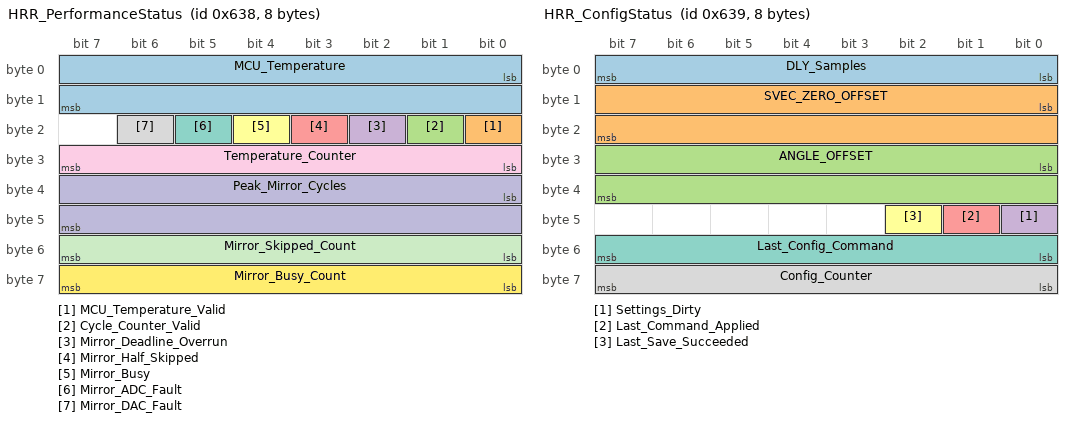
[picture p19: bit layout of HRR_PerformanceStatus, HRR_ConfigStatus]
BO_ 1592 HRR_PerformanceStatus: 8 STM32G474_HRR
 SG_ MCU_Temperature : 0|16@1- (1,0) [-32768|32767] "degC" CAN_Master
 SG_ MCU_Temperature_Valid : 16|1@1+ (1,0) [0|1] "" CAN_Master
 SG_ Cycle_Counter_Valid : 17|1@1+ (1,0) [0|1] "" CAN_Master
 SG_ Mirror_Deadline_Overrun : 18|1@1+ (1,0) [0|1] "" CAN_Master
 SG_ Mirror_Half_Skipped : 19|1@1+ (1,0) [0|1] "" CAN_Master
 SG_ Mirror_Busy : 20|1@1+ (1,0) [0|1] "" CAN_Master
 SG_ Mirror_ADC_Fault : 21|1@1+ (1,0) [0|1] "" CAN_Master
 SG_ Mirror_DAC_Fault : 22|1@1+ (1,0) [0|1] "" CAN_Master
 SG_ Temperature_Counter : 24|8@1+ (1,0) [0|255] "" CAN_Master
 SG_ Peak_Mirror_Cycles : 32|16@1+ (8,0) [0|524280] "cycles" CAN_Master
 SG_ Mirror_Skipped_Count : 48|8@1+ (1,0) [0|255] "events" CAN_Master
 SG_ Mirror_Busy_Count : 56|8@1+ (1,0) [0|255] "events" CAN_Master
CM_ BO_ 1592 "STM32 temperature and live-mirror performance status, sent at 1 Hz. Bytes 0..3 preserve the former temperature layout. Peak_Mirror_Cycles is the maximum measured during the preceding report interval and resets atomically at each report. Mirror_Deadline_Overrun and event/fault metrics remain sticky until the live mirror restarts. The 170 MHz, 640 us mirror deadline is 108800 cycles; consumers must require Cycle_Counter_Valid before using timing.";

BO_ 1593 HRR_ConfigStatus: 8 STM32G474_HRR
 SG_ DLY_Samples : 0|8@1+ (1,0) [0|127] "samples" CAN_Master
 SG_ SVEC_ZERO_OFFSET : 8|16@1- (0.1,0) [-13.5|13.5] "deg" CAN_Master
 SG_ ANGLE_OFFSET : 24|16@1- (0.1,0) [-90|90] "deg" CAN_Master
 SG_ Settings_Dirty : 40|1@1+ (1,0) [0|1] "" CAN_Master
 SG_ Last_Command_Applied : 41|1@1+ (1,0) [0|1] "" CAN_Master
 SG_ Last_Save_Succeeded : 42|1@1+ (1,0) [0|1] "" CAN_Master
 SG_ Last_Config_Command : 48|8@1+ (1,0) [0|255] "" CAN_Master
 SG_ Config_Counter : 56|8@1+ (1,0) [0|255] "" CAN_Master
CM_ BO_ 1593 "Active SVEC settings and acknowledgement for keyed 0x603 commands. Settings_Dirty means the active DLY or offsets differ from the last successfully loaded/saved values. Config_Counter increments for each valid keyed command; Last_Command_Applied reports whether that command was accepted, and Last_Save_Succeeded is set only after command 9 successfully commits the packed current settings record.";

BA_DEF_ BO_ "GenMsgCycleTime" INT 0 65535;
BA_ "GenMsgCycleTime" BO_ 1584 100;
BA_ "GenMsgCycleTime" BO_ 1585 100;
BA_ "GenMsgCycleTime" BO_ 1586 100;
BA_ "GenMsgCycleTime" BO_ 1587 100;
BA_ "GenMsgCycleTime" BO_ 1588 100;
BA_ "GenMsgCycleTime" BO_ 1589 100;
BA_ "GenMsgCycleTime" BO_ 1590 10;
BA_ "GenMsgCycleTime" BO_ 1591 100;
BA_ "GenMsgCycleTime" BO_ 1592 1000;
BA_ "GenMsgCycleTime" BO_ 1593 100;

VAL_ 1539 Config_Command 1 "DLY_SAMPLES" 2 "PHASEMATCH_HZ" 3 "ANGLE_OFFSET_TENTHS" 4 "RESOLVER_CAL_START" 5 "RESOLVER_CAL_FINISH_SAVE" 6 "RESOLVER_CAL_ABORT" 7 "RESOLVER_CAL_MODE" 8 "SVEC_ZERO_OFFSET_TENTHS" 9 "SVEC_SAVE_CURRENT" 10 "TRUE_ANGLE_REFERENCE" 11 "CAL_IN_M00_Q20" 12 "CAL_IN_M01_Q20" 13 "CAL_IN_M10_Q20" 14 "CAL_IN_M11_Q20" 15 "CAL_OU_M00_Q20" 16 "CAL_OU_M01_Q20" 17 "CAL_OU_M10_Q20" 18 "CAL_OU_M11_Q20" 19 "CAL_PHASE_PER_STEER_Q20" 20 "CAL_FIT_METRICS";
VAL_ 1540 Test_Command 0 "SAFE_EXIT" 1 "DIGITAL" 2 "DAC_PA4" 3 "DAC_PA5" 4 "DAC_BOTH";
VAL_ 1540 REL_Test 0 "OFF" 1 "ON";
VAL_ 1540 RELE_Test 0 "OFF" 1 "ON";
VAL_ 1540 LED_PC6_Test 0 "OFF" 1 "ON";
VAL_ 1540 LED_PC11_Test 0 "OFF" 1 "ON";
VAL_ 352 REL_Cmd 0 "OFF" 1 "ON";
VAL_ 352 RELE_Cmd 0 "OFF" 1 "ON";
VAL_ 710 BRAKE_PRESSED 0 "NOT_PRESSED" 1 "PRESSED";
VAL_ 1585 REL_State 0 "OFF" 1 "ON";
VAL_ 1585 RELE_State 0 "OFF" 1 "ON";
VAL_ 1585 RC_Minus 0 "LOW" 1 "HIGH";
VAL_ 1585 RC_Plus 0 "LOW" 1 "HIGH";
VAL_ 1588 REL_Measured 0 "OFF" 1 "ON";
VAL_ 1588 RELE_Measured 0 "OFF" 1 "ON";
VAL_ 1588 OU_Angle_Valid 0 "INVALID" 1 "VALID";
VAL_ 1588 IN_Angle_Valid 0 "INVALID" 1 "VALID";
VAL_ 1588 Brake_Frame_Seen 0 "NOT_SEEN" 1 "SEEN";
VAL_ 1588 Brake_Frame_Fresh 0 "STALE" 1 "FRESH";
VAL_ 1588 Brake_Pressed 0 "NOT_PRESSED" 1 "PRESSED";
VAL_ 1588 Brake_Interlock 0 "CLEAR" 1 "ACTIVE";
VAL_ 1588 Torque_Frame_Accepted 0 "NOT_ACCEPTED" 1 "ACCEPTED";
VAL_ 1588 SVEC_Centers_Valid 0 "INVALID" 1 "VALID";
VAL_ 1588 Mirror_Running 0 "STOPPED" 1 "RUNNING";
VAL_ 1588 SVEC_Guard_Enabled 0 "DISABLED" 1 "ENABLED";
VAL_ 1588 SVEC_Guard_Angles_Valid 0 "INVALID" 1 "VALID";
VAL_ 1588 CANCTR_Enabled 0 "DISABLED" 1 "ENABLED";
VAL_ 1588 Torque_Frame_Fresh 0 "STALE" 1 "FRESH";
VAL_ 1588 Torque_Interlock 0 "CLEAR" 1 "ACTIVE";
VAL_ 1589 Calibration_Running 0 "IDLE" 1 "RUNNING";
VAL_ 1589 Calibration_Valid 0 "INVALID" 1 "VALID";
VAL_ 1589 Calibration_Enabled 0 "DISABLED" 1 "ENABLED";
VAL_ 1589 Calibration_Failed 0 "OK" 1 "FAILED";
VAL_ 1589 Calibration_Params_Complete 0 "INCOMPLETE" 1 "COMPLETE";
VAL_ 1589 IN_Vector_Valid 0 "INVALID" 1 "VALID";
VAL_ 1589 OU_Vector_Valid 0 "INVALID" 1 "VALID";
VAL_ 1589 Legacy_Angles_Active 0 "CALIBRATED" 1 "LEGACY";
VAL_ 1589 Calibration_Failure_Reason 0 "NONE" 1 "UNSAFE" 2 "SESSION" 3 "INCOMPLETE" 4 "COEFFICIENT" 5 "FIT" 6 "NVM" 7 "TIMEOUT" 8 "CANCTR_DISABLED" 9 "TEST_MODE" 10 "MIRROR_STOPPED" 11 "SVEC_DELTA" 12 "RELAY_COMMAND" 13 "RELAY_FEEDBACK" 14 "TORQUE_INTERLOCK" 19 "IN_VECTOR" 20 "OU_VECTOR" 21 "FLASH_ERASE_RESET" 22 "FLASH_PROGRAM_RESET" 23 "FLASH_VERIFY_RESET" 24 "FLASH_COMMIT_RESET" 25 "FLASH_VALIDATE_RESET";
VAL_ 956 GEAR 0 "D" 1 "S" 8 "N" 16 "R" 32 "P";
VAL_ 1616 TURN_SIGNALS 0 "OFF" 1 "LEFT" 2 "RIGHT";
